VERSION ""

NS_ :

BS_:

BU_: CART BMS TB LV INV

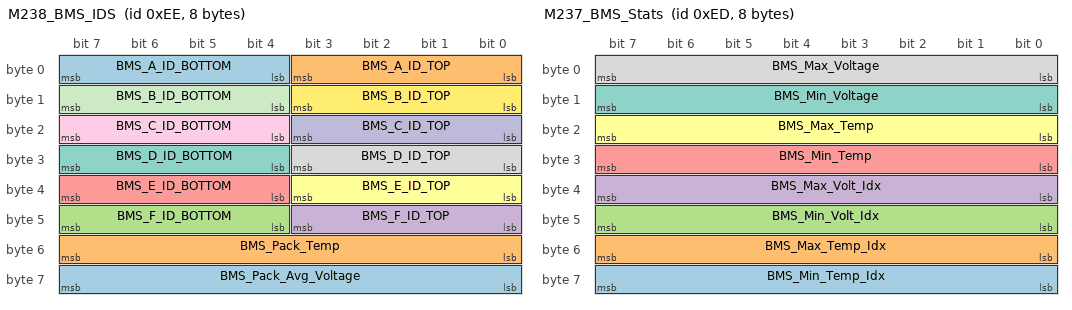
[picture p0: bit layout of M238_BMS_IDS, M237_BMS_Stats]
BO_ 238 M238_BMS_IDS: 8 Vector__XXX
 SG_ BMS_Pack_Avg_Voltage : 56|8@1+ (0.01,1.8) [1.8|4.35] "" Vector__XXX
 SG_ BMS_Pack_Temp : 48|8@1+ (0.25,0) [0|63.75] "" Vector__XXX
 SG_ BMS_F_ID_BOTTOM : 44|4@1+ (1,0) [0|15] "" Vector__XXX
 SG_ BMS_F_ID_TOP : 40|4@1+ (1,0) [0|15] "" Vector__XXX
 SG_ BMS_E_ID_BOTTOM : 36|4@1+ (1,0) [0|15] "" Vector__XXX
 SG_ BMS_E_ID_TOP : 32|4@1+ (1,0) [0|15] "" Vector__XXX
 SG_ BMS_D_ID_BOTTOM : 28|4@1+ (1,0) [0|15] "" Vector__XXX
 SG_ BMS_D_ID_TOP : 24|4@1+ (1,0) [0|15] "" Vector__XXX
 SG_ BMS_C_ID_BOTTOM : 20|4@1+ (1,0) [0|15] "" Vector__XXX
 SG_ BMS_C_ID_TOP : 16|4@1+ (1,0) [0|15] "" Vector__XXX
 SG_ BMS_B_ID_BOTTOM : 12|4@1+ (1,0) [0|15] "" Vector__XXX
 SG_ BMS_B_ID_TOP : 8|4@1+ (1,0) [0|15] "" Vector__XXX
 SG_ BMS_A_ID_BOTTOM : 4|4@1+ (1,0) [0|15] "" Vector__XXX
 SG_ BMS_A_ID_TOP : 0|4@1+ (1,0) [0|15] "" Vector__XXX

BO_ 237 M237_BMS_Stats: 8 Vector__XXX
 SG_ BMS_Min_Temp_Idx : 56|8@1+ (1,0) [0|0] "" Vector__XXX
 SG_ BMS_Max_Temp_Idx : 48|8@1+ (1,0) [0|0] "" Vector__XXX
 SG_ BMS_Min_Volt_Idx : 40|8@1+ (1,0) [0|0] "" Vector__XXX
 SG_ BMS_Max_Volt_Idx : 32|8@1+ (1,0) [0|0] "" Vector__XXX
 SG_ BMS_Min_Temp : 24|8@1+ (0.25,0) [0|63.75] "" Vector__XXX
 SG_ BMS_Max_Temp : 16|8@1+ (0.25,0) [0|63.75] "" Vector__XXX
 SG_ BMS_Min_Voltage : 8|8@1+ (0.01,1.8) [1.8|4.35] "" Vector__XXX
 SG_ BMS_Max_Voltage : 0|8@1+ (0.01,1.8) [1.8|4.35] "" Vector__XXX

BO_ 6 M006_Pack_Sense: 7 TB
 SG_ TB_Temp_Ambient : 48|8@1+ (0.5,-10) [-10|117.5] "C" Vector__XXX
 SG_ TB_Temp_VSense : 40|8@1+ (0.5,-10) [-10|117.5] "C" Vector__XXX
 SG_ TB_Temp_Power : 32|8@1+ (0.5,-10) [-10|117.5] "C" Vector__XXX
 SG_ TB_Temp_Precharge : 24|8@1+ (0.5,-10) [-10|117.5] "C" Vector__XXX
 SG_ TB_Bat_VSense : 12|12@1+ (0.25,0) [0|1023.75] "V" Vector__XXX
 SG_ TB_TS_VSense : 0|12@1+ (0.25,0) [0|1023.75] "V" Vector__XXX

BO_ 20 M020_Charger_to_Pack: 3 CART
 SG_ Charger_Balancing_Enable : 0|1@1+ (1,0) [0|1] "" Vector__XXX
 SG_ Charger_Current : 8|16@1- (0.1,0) [-3276.8|3276.7] "current:A" Vector__XXX

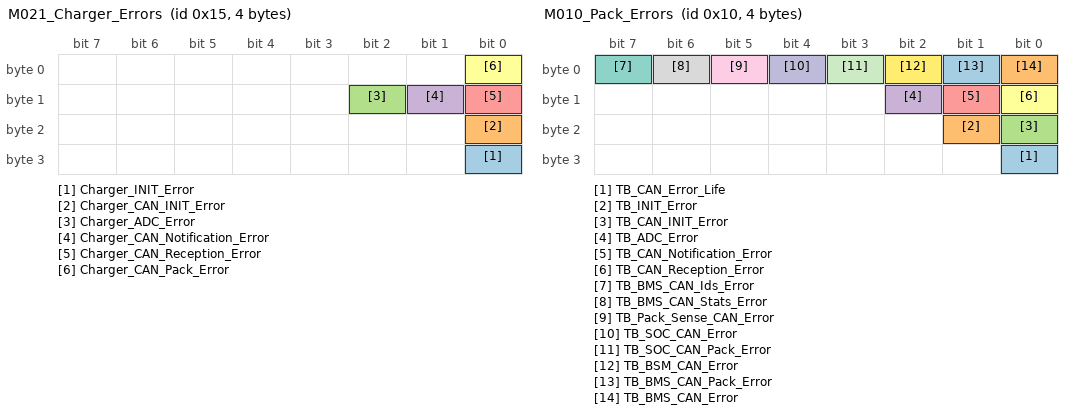
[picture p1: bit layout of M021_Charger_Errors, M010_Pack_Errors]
BO_ 21 M021_Charger_Errors: 4 CART
 SG_ Charger_INIT_Error : 24|1@1+ (1,0) [0|1] "" Vector__XXX
 SG_ Charger_CAN_INIT_Error : 16|1@1+ (1,0) [0|1] "" Vector__XXX
 SG_ Charger_ADC_Error : 10|1@1+ (1,0) [0|1] "" Vector__XXX
 SG_ Charger_CAN_Notification_Error : 9|1@1+ (1,0) [0|1] "" Vector__XXX
 SG_ Charger_CAN_Reception_Error : 8|1@1+ (1,0) [0|1] "" Vector__XXX
 SG_ Charger_CAN_Pack_Error : 0|1@1+ (1,0) [0|1] "" Vector__XXX

BO_ 16 M010_Pack_Errors: 4 TB
 SG_ TB_CAN_Error_Life : 24|1@1- (1,0) [0|0] "" Vector__XXX
 SG_ TB_INIT_Error : 17|1@1+ (1,0) [0|1] "" Vector__XXX
 SG_ TB_CAN_INIT_Error : 16|1@1+ (1,0) [0|1] "" Vector__XXX
 SG_ TB_ADC_Error : 10|1@1+ (1,0) [0|1] "" Vector__XXX
 SG_ TB_CAN_Notification_Error : 9|1@1+ (1,0) [0|1] "" Vector__XXX
 SG_ TB_CAN_Reception_Error : 8|1@1+ (1,0) [0|1] "" Vector__XXX
 SG_ TB_BMS_CAN_Ids_Error : 7|1@1+ (1,0) [0|1] "" Vector__XXX
 SG_ TB_BMS_CAN_Stats_Error : 6|1@1+ (1,0) [0|1] "" Vector__XXX
 SG_ TB_Pack_Sense_CAN_Error : 5|1@1+ (1,0) [0|1] "" Vector__XXX
 SG_ TB_SOC_CAN_Error : 4|1@1+ (1,0) [0|1] "" Vector__XXX
 SG_ TB_SOC_CAN_Pack_Error : 3|1@1+ (1,0) [0|1] "" Vector__XXX
 SG_ TB_BSM_CAN_Error : 2|1@1+ (1,0) [0|1] "" Vector__XXX
 SG_ TB_BMS_CAN_Pack_Error : 1|1@1+ (1,0) [0|1] "" Vector__XXX
 SG_ TB_BMS_CAN_Error : 0|1@1+ (1,0) [0|1] "" Vector__XXX

BO_ 236 M236_BMS_Pack: 8 BMS
 SG_ BMS_F_TEMP_SENSE_Fault : 60|1@1+ (1,0) [0|1] "" Vector__XXX
 SG_ BMS_F_COMMS_Fault : 59|1@1+ (1,0) [0|1] "" Vector__XXX
 SG_ BMS_F_OT_Fault : 58|1@1+ (1,0) [0|1] "" Vector__XXX
 SG_ BMS_F_UV_Fault : 57|1@1+ (1,0) [0|1] "" Vector__XXX
 SG_ BMS_F_OV_Fault : 56|1@1+ (1,0) [0|1] "" Vector__XXX
 SG_ BMS_E_TEMP_SENSE_Fault : 52|1@1+ (1,0) [0|1] "" Vector__XXX
 SG_ BMS_E_COMMS_Fault : 51|1@1+ (1,0) [0|1] "" Vector__XXX
 SG_ BMS_E_OT_Fault : 50|1@1+ (1,0) [0|1] "" Vector__XXX
 SG_ BMS_E_UV_Fault : 49|1@1+ (1,0) [0|1] "" Vector__XXX
 SG_ BMS_E_OV_Fault : 48|1@1+ (1,0) [0|1] "" Vector__XXX
 SG_ BMS_D_TEMP_SENSE_Fault : 44|1@1+ (1,0) [0|1] "" Vector__XXX
 SG_ BMS_D_COMMS_Fault : 43|1@1+ (1,0) [0|1] "" Vector__XXX
 SG_ BMS_D_OT_Fault : 42|1@1+ (1,0) [0|1] "" Vector__XXX
 SG_ BMS_D_UV_Fault : 41|1@1+ (1,0) [0|1] "" Vector__XXX
 SG_ BMS_D_OV_Fault : 40|1@1+ (1,0) [0|1] "" Vector__XXX
 SG_ BMS_C_TEMP_SENSE_Fault : 36|1@1+ (1,0) [0|1] "" Vector__XXX
 SG_ BMS_C_COMMS_Fault : 35|1@1+ (1,0) [0|1] "" Vector__XXX
 SG_ BMS_C_OT_Fault : 34|1@1+ (1,0) [0|1] "" Vector__XXX
 SG_ BMS_C_UV_Fault : 33|1@1+ (1,0) [0|1] "" Vector__XXX
 SG_ BMS_C_OV_Fault : 32|1@1+ (1,0) [0|1] "" Vector__XXX
 SG_ BMS_B_TEMP_SENSE_Fault : 28|1@1+ (1,0) [0|1] "" Vector__XXX
 SG_ BMS_B_COMMS_Fault : 27|1@1+ (1,0) [0|1] "" Vector__XXX
 SG_ BMS_B_OT_Fault : 26|1@1+ (1,0) [0|1] "" Vector__XXX
 SG_ BMS_B_UV_Fault : 25|1@1+ (1,0) [0|1] "" Vector__XXX
 SG_ BMS_B_OV_Fault : 24|1@1+ (1,0) [0|1] "" Vector__XXX
 SG_ BMS_Balancing_Done : 23|1@1+ (1,0) [0|1] "" Vector__XXX
 SG_ BMS_A_TEMP_SENSE_Fault : 20|1@1+ (1,0) [0|1] "" Vector__XXX
 SG_ BMS_A_COMMS_Fault : 19|1@1+ (1,0) [0|1] "" Vector__XXX
 SG_ BMS_A_OT_Fault : 18|1@1+ (1,0) [0|1] "" Vector__XXX
 SG_ BMS_A_UV_Fault : 17|1@1+ (1,0) [0|1] "" Vector__XXX
 SG_ BMS_A_OV_Fault : 16|1@1+ (1,0) [0|1] "" Vector__XXX
 SG_ BMS_Pack_Voltage : 0|16@1+ (0.01,0) [0|655.35] "" Vector__XXX

BO_ 240 M240_BMS_SOC_Pack: 6 BMS
 SG_ BMS_SOC_Uncertainty : 32|16@1+ (1.52590218966964E-05,0) [0|1] "" Vector__XXX
 SG_ BMS_SOC_Pack_Capacity : 16|16@1+ (0.02285191119,0) [0|1497.59999983665] "" Vector__XXX
 SG_ BMS_SOC_Pack : 0|16@1+ (1.52590218966964E-05,0) [0|1] "" Vector__XXX

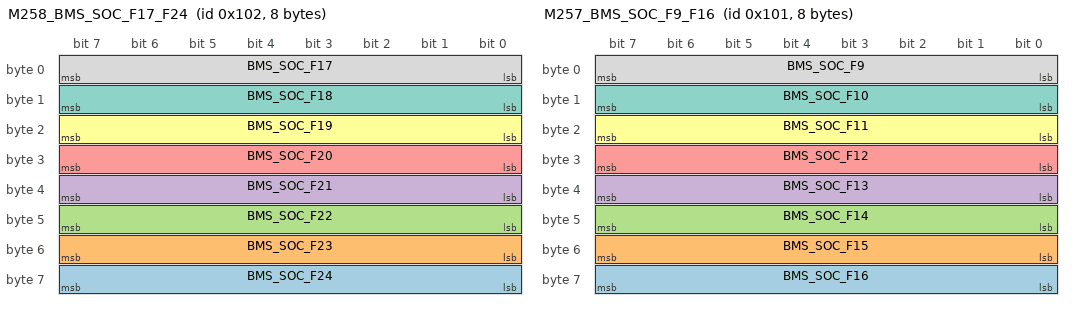
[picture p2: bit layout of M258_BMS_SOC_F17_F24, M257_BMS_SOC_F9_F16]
BO_ 258 M258_BMS_SOC_F17_F24: 8 BMS
 SG_ BMS_SOC_F24 : 56|8@1+ (0.00392156862745098,0) [0|1] "" Vector__XXX
 SG_ BMS_SOC_F23 : 48|8@1+ (0.00392156862745098,0) [0|1] "" Vector__XXX
 SG_ BMS_SOC_F22 : 40|8@1+ (0.00392156862745098,0) [0|1] "" Vector__XXX
 SG_ BMS_SOC_F21 : 32|8@1+ (0.00392156862745098,0) [0|1] "" Vector__XXX
 SG_ BMS_SOC_F20 : 24|8@1+ (0.00392156862745098,0) [0|1] "" Vector__XXX
 SG_ BMS_SOC_F19 : 16|8@1+ (0.00392156862745098,0) [0|1] "" Vector__XXX
 SG_ BMS_SOC_F18 : 8|8@1+ (0.00392156862745098,0) [0|1] "" Vector__XXX
 SG_ BMS_SOC_F17 : 0|8@1+ (0.00392156862745098,0) [0|1] "" Vector__XXX

BO_ 257 M257_BMS_SOC_F9_F16: 8 BMS
 SG_ BMS_SOC_F16 : 56|8@1+ (0.00392156862745098,0) [0|1] "" Vector__XXX
 SG_ BMS_SOC_F15 : 48|8@1+ (0.00392156862745098,0) [0|1] "" Vector__XXX
 SG_ BMS_SOC_F14 : 40|8@1+ (0.00392156862745098,0) [0|1] "" Vector__XXX
 SG_ BMS_SOC_F13 : 32|8@1+ (0.00392156862745098,0) [0|1] "" Vector__XXX
 SG_ BMS_SOC_F12 : 24|8@1+ (0.00392156862745098,0) [0|1] "" Vector__XXX
 SG_ BMS_SOC_F11 : 16|8@1+ (0.00392156862745098,0) [0|1] "" Vector__XXX
 SG_ BMS_SOC_F10 : 8|8@1+ (0.00392156862745098,0) [0|1] "" Vector__XXX
 SG_ BMS_SOC_F9 : 0|8@1+ (0.00392156862745098,0) [0|1] "" Vector__XXX

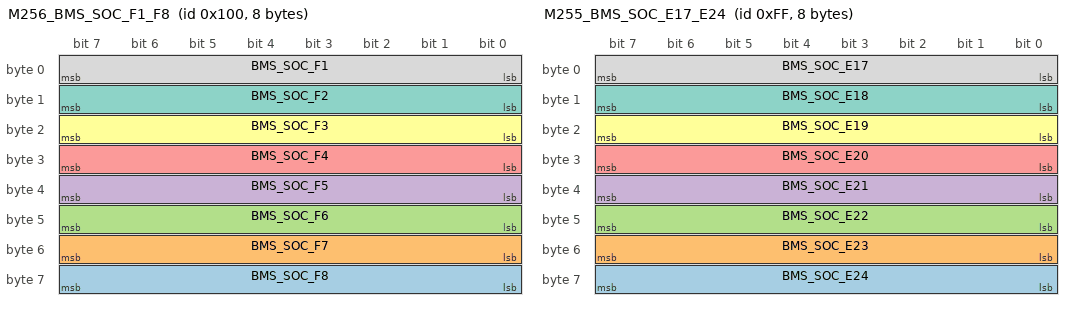
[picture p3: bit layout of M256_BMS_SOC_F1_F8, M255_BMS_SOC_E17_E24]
BO_ 256 M256_BMS_SOC_F1_F8: 8 BMS
 SG_ BMS_SOC_F8 : 56|8@1+ (0.00392156862745098,0) [0|1] "" Vector__XXX
 SG_ BMS_SOC_F7 : 48|8@1+ (0.00392156862745098,0) [0|1] "" Vector__XXX
 SG_ BMS_SOC_F6 : 40|8@1+ (0.00392156862745098,0) [0|1] "" Vector__XXX
 SG_ BMS_SOC_F5 : 32|8@1+ (0.00392156862745098,0) [0|1] "" Vector__XXX
 SG_ BMS_SOC_F4 : 24|8@1+ (0.00392156862745098,0) [0|1] "" Vector__XXX
 SG_ BMS_SOC_F3 : 16|8@1+ (0.00392156862745098,0) [0|1] "" Vector__XXX
 SG_ BMS_SOC_F2 : 8|8@1+ (0.00392156862745098,0) [0|1] "" Vector__XXX
 SG_ BMS_SOC_F1 : 0|8@1+ (0.00392156862745098,0) [0|1] "" Vector__XXX

BO_ 255 M255_BMS_SOC_E17_E24: 8 BMS
 SG_ BMS_SOC_E24 : 56|8@1+ (0.00392156862745098,0) [0|1] "" Vector__XXX
 SG_ BMS_SOC_E23 : 48|8@1+ (0.00392156862745098,0) [0|1] "" Vector__XXX
 SG_ BMS_SOC_E22 : 40|8@1+ (0.00392156862745098,0) [0|1] "" Vector__XXX
 SG_ BMS_SOC_E21 : 32|8@1+ (0.00392156862745098,0) [0|1] "" Vector__XXX
 SG_ BMS_SOC_E20 : 24|8@1+ (0.00392156862745098,0) [0|1] "" Vector__XXX
 SG_ BMS_SOC_E19 : 16|8@1+ (0.00392156862745098,0) [0|1] "" Vector__XXX
 SG_ BMS_SOC_E18 : 8|8@1+ (0.00392156862745098,0) [0|1] "" Vector__XXX
 SG_ BMS_SOC_E17 : 0|8@1+ (0.00392156862745098,0) [0|1] "" Vector__XXX

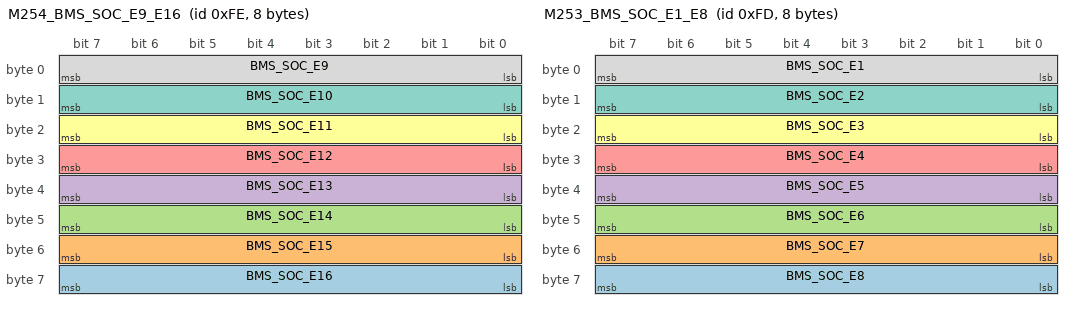
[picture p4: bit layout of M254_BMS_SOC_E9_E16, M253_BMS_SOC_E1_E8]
BO_ 254 M254_BMS_SOC_E9_E16: 8 BMS
 SG_ BMS_SOC_E16 : 56|8@1+ (0.00392156862745098,0) [0|1] "" Vector__XXX
 SG_ BMS_SOC_E15 : 48|8@1+ (0.00392156862745098,0) [0|1] "" Vector__XXX
 SG_ BMS_SOC_E14 : 40|8@1+ (0.00392156862745098,0) [0|1] "" Vector__XXX
 SG_ BMS_SOC_E13 : 32|8@1+ (0.00392156862745098,0) [0|1] "" Vector__XXX
 SG_ BMS_SOC_E12 : 24|8@1+ (0.00392156862745098,0) [0|1] "" Vector__XXX
 SG_ BMS_SOC_E11 : 16|8@1+ (0.00392156862745098,0) [0|1] "" Vector__XXX
 SG_ BMS_SOC_E10 : 8|8@1+ (0.00392156862745098,0) [0|1] "" Vector__XXX
 SG_ BMS_SOC_E9 : 0|8@1+ (0.00392156862745098,0) [0|1] "" Vector__XXX

BO_ 253 M253_BMS_SOC_E1_E8: 8 BMS
 SG_ BMS_SOC_E8 : 56|8@1+ (0.00392156862745098,0) [0|1] "" Vector__XXX
 SG_ BMS_SOC_E7 : 48|8@1+ (0.00392156862745098,0) [0|1] "" Vector__XXX
 SG_ BMS_SOC_E6 : 40|8@1+ (0.00392156862745098,0) [0|1] "" Vector__XXX
 SG_ BMS_SOC_E5 : 32|8@1+ (0.00392156862745098,0) [0|1] "" Vector__XXX
 SG_ BMS_SOC_E4 : 24|8@1+ (0.00392156862745098,0) [0|1] "" Vector__XXX
 SG_ BMS_SOC_E3 : 16|8@1+ (0.00392156862745098,0) [0|1] "" Vector__XXX
 SG_ BMS_SOC_E2 : 8|8@1+ (0.00392156862745098,0) [0|1] "" Vector__XXX
 SG_ BMS_SOC_E1 : 0|8@1+ (0.00392156862745098,0) [0|1] "" Vector__XXX

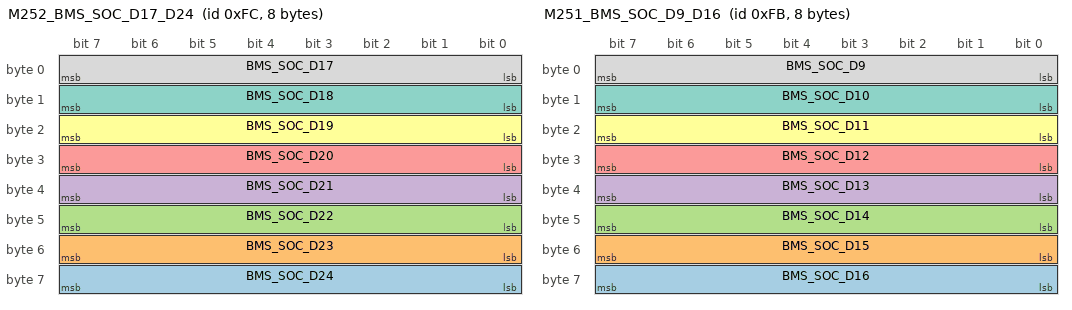
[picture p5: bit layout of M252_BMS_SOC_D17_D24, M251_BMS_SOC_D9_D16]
BO_ 252 M252_BMS_SOC_D17_D24: 8 BMS
 SG_ BMS_SOC_D24 : 56|8@1+ (0.00392156862745098,0) [0|1] "" Vector__XXX
 SG_ BMS_SOC_D23 : 48|8@1+ (0.00392156862745098,0) [0|1] "" Vector__XXX
 SG_ BMS_SOC_D22 : 40|8@1+ (0.00392156862745098,0) [0|1] "" Vector__XXX
 SG_ BMS_SOC_D21 : 32|8@1+ (0.00392156862745098,0) [0|1] "" Vector__XXX
 SG_ BMS_SOC_D20 : 24|8@1+ (0.00392156862745098,0) [0|1] "" Vector__XXX
 SG_ BMS_SOC_D19 : 16|8@1+ (0.00392156862745098,0) [0|1] "" Vector__XXX
 SG_ BMS_SOC_D18 : 8|8@1+ (0.00392156862745098,0) [0|1] "" Vector__XXX
 SG_ BMS_SOC_D17 : 0|8@1+ (0.00392156862745098,0) [0|1] "" Vector__XXX

BO_ 251 M251_BMS_SOC_D9_D16: 8 BMS
 SG_ BMS_SOC_D16 : 56|8@1+ (0.00392156862745098,0) [0|1] "" Vector__XXX
 SG_ BMS_SOC_D15 : 48|8@1+ (0.00392156862745098,0) [0|1] "" Vector__XXX
 SG_ BMS_SOC_D14 : 40|8@1+ (0.00392156862745098,0) [0|1] "" Vector__XXX
 SG_ BMS_SOC_D13 : 32|8@1+ (0.00392156862745098,0) [0|1] "" Vector__XXX
 SG_ BMS_SOC_D12 : 24|8@1+ (0.00392156862745098,0) [0|1] "" Vector__XXX
 SG_ BMS_SOC_D11 : 16|8@1+ (0.00392156862745098,0) [0|1] "" Vector__XXX
 SG_ BMS_SOC_D10 : 8|8@1+ (0.00392156862745098,0) [0|1] "" Vector__XXX
 SG_ BMS_SOC_D9 : 0|8@1+ (0.00392156862745098,0) [0|1] "" Vector__XXX

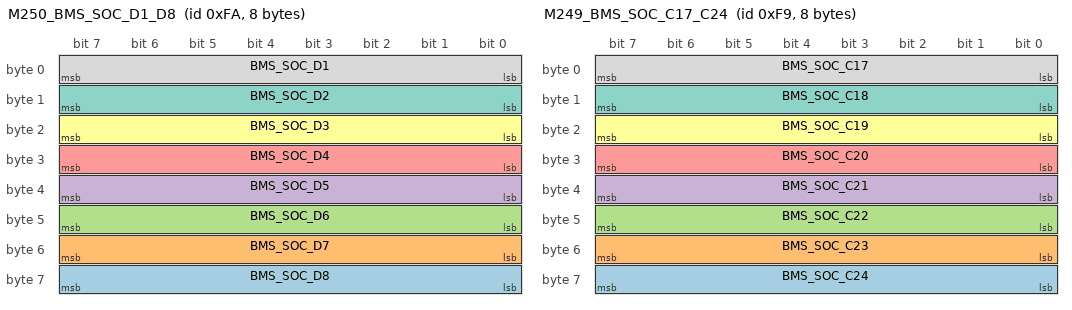
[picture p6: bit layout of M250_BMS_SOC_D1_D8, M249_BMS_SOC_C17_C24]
BO_ 250 M250_BMS_SOC_D1_D8: 8 BMS
 SG_ BMS_SOC_D8 : 56|8@1+ (0.00392156862745098,0) [0|1] "" Vector__XXX
 SG_ BMS_SOC_D7 : 48|8@1+ (0.00392156862745098,0) [0|1] "" Vector__XXX
 SG_ BMS_SOC_D6 : 40|8@1+ (0.00392156862745098,0) [0|1] "" Vector__XXX
 SG_ BMS_SOC_D5 : 32|8@1+ (0.00392156862745098,0) [0|1] "" Vector__XXX
 SG_ BMS_SOC_D4 : 24|8@1+ (0.00392156862745098,0) [0|1] "" Vector__XXX
 SG_ BMS_SOC_D3 : 16|8@1+ (0.00392156862745098,0) [0|1] "" Vector__XXX
 SG_ BMS_SOC_D2 : 8|8@1+ (0.00392156862745098,0) [0|1] "" Vector__XXX
 SG_ BMS_SOC_D1 : 0|8@1+ (0.00392156862745098,0) [0|1] "" Vector__XXX

BO_ 249 M249_BMS_SOC_C17_C24: 8 BMS
 SG_ BMS_SOC_C24 : 56|8@1+ (0.00392156862745098,0) [0|1] "" Vector__XXX
 SG_ BMS_SOC_C23 : 48|8@1+ (0.00392156862745098,0) [0|1] "" Vector__XXX
 SG_ BMS_SOC_C22 : 40|8@1+ (0.00392156862745098,0) [0|1] "" Vector__XXX
 SG_ BMS_SOC_C21 : 32|8@1+ (0.00392156862745098,0) [0|1] "" Vector__XXX
 SG_ BMS_SOC_C20 : 24|8@1+ (0.00392156862745098,0) [0|1] "" Vector__XXX
 SG_ BMS_SOC_C19 : 16|8@1+ (0.00392156862745098,0) [0|1] "" Vector__XXX
 SG_ BMS_SOC_C18 : 8|8@1+ (0.00392156862745098,0) [0|1] "" Vector__XXX
 SG_ BMS_SOC_C17 : 0|8@1+ (0.00392156862745098,0) [0|1] "" Vector__XXX

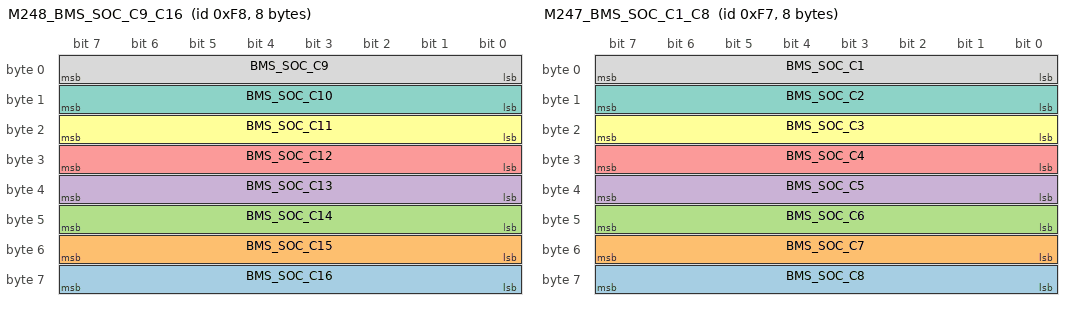
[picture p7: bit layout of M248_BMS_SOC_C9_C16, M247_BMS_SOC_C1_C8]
BO_ 248 M248_BMS_SOC_C9_C16: 8 BMS
 SG_ BMS_SOC_C16 : 56|8@1+ (0.00392156862745098,0) [0|1] "" Vector__XXX
 SG_ BMS_SOC_C15 : 48|8@1+ (0.00392156862745098,0) [0|1] "" Vector__XXX
 SG_ BMS_SOC_C14 : 40|8@1+ (0.00392156862745098,0) [0|1] "" Vector__XXX
 SG_ BMS_SOC_C13 : 32|8@1+ (0.00392156862745098,0) [0|1] "" Vector__XXX
 SG_ BMS_SOC_C12 : 24|8@1+ (0.00392156862745098,0) [0|1] "" Vector__XXX
 SG_ BMS_SOC_C11 : 16|8@1+ (0.00392156862745098,0) [0|1] "" Vector__XXX
 SG_ BMS_SOC_C10 : 8|8@1+ (0.00392156862745098,0) [0|1] "" Vector__XXX
 SG_ BMS_SOC_C9 : 0|8@1+ (0.00392156862745098,0) [0|1] "" Vector__XXX

BO_ 247 M247_BMS_SOC_C1_C8: 8 BMS
 SG_ BMS_SOC_C8 : 56|8@1+ (0.00392156862745098,0) [0|1] "" Vector__XXX
 SG_ BMS_SOC_C7 : 48|8@1+ (0.00392156862745098,0) [0|1] "" Vector__XXX
 SG_ BMS_SOC_C6 : 40|8@1+ (0.00392156862745098,0) [0|1] "" Vector__XXX
 SG_ BMS_SOC_C5 : 32|8@1+ (0.00392156862745098,0) [0|1] "" Vector__XXX
 SG_ BMS_SOC_C4 : 24|8@1+ (0.00392156862745098,0) [0|1] "" Vector__XXX
 SG_ BMS_SOC_C3 : 16|8@1+ (0.00392156862745098,0) [0|1] "" Vector__XXX
 SG_ BMS_SOC_C2 : 8|8@1+ (0.00392156862745098,0) [0|1] "" Vector__XXX
 SG_ BMS_SOC_C1 : 0|8@1+ (0.00392156862745098,0) [0|1] "" Vector__XXX

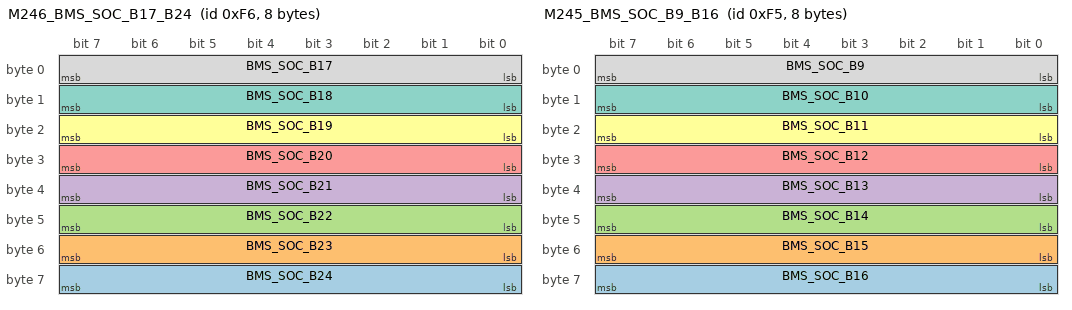
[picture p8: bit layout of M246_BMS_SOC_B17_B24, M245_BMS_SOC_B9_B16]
BO_ 246 M246_BMS_SOC_B17_B24: 8 BMS
 SG_ BMS_SOC_B24 : 56|8@1+ (0.00392156862745098,0) [0|1] "" Vector__XXX
 SG_ BMS_SOC_B23 : 48|8@1+ (0.00392156862745098,0) [0|1] "" Vector__XXX
 SG_ BMS_SOC_B22 : 40|8@1+ (0.00392156862745098,0) [0|1] "" Vector__XXX
 SG_ BMS_SOC_B21 : 32|8@1+ (0.00392156862745098,0) [0|1] "" Vector__XXX
 SG_ BMS_SOC_B20 : 24|8@1+ (0.00392156862745098,0) [0|1] "" Vector__XXX
 SG_ BMS_SOC_B19 : 16|8@1+ (0.00392156862745098,0) [0|1] "" Vector__XXX
 SG_ BMS_SOC_B18 : 8|8@1+ (0.00392156862745098,0) [0|1] "" Vector__XXX
 SG_ BMS_SOC_B17 : 0|8@1+ (0.00392156862745098,0) [0|1] "" Vector__XXX

BO_ 245 M245_BMS_SOC_B9_B16: 8 BMS
 SG_ BMS_SOC_B16 : 56|8@1+ (0.00392156862745098,0) [0|1] "" Vector__XXX
 SG_ BMS_SOC_B15 : 48|8@1+ (0.00392156862745098,0) [0|1] "" Vector__XXX
 SG_ BMS_SOC_B14 : 40|8@1+ (0.00392156862745098,0) [0|1] "" Vector__XXX
 SG_ BMS_SOC_B13 : 32|8@1+ (0.00392156862745098,0) [0|1] "" Vector__XXX
 SG_ BMS_SOC_B12 : 24|8@1+ (0.00392156862745098,0) [0|1] "" Vector__XXX
 SG_ BMS_SOC_B11 : 16|8@1+ (0.00392156862745098,0) [0|1] "" Vector__XXX
 SG_ BMS_SOC_B10 : 8|8@1+ (0.00392156862745098,0) [0|1] "" Vector__XXX
 SG_ BMS_SOC_B9 : 0|8@1+ (0.00392156862745098,0) [0|1] "" Vector__XXX

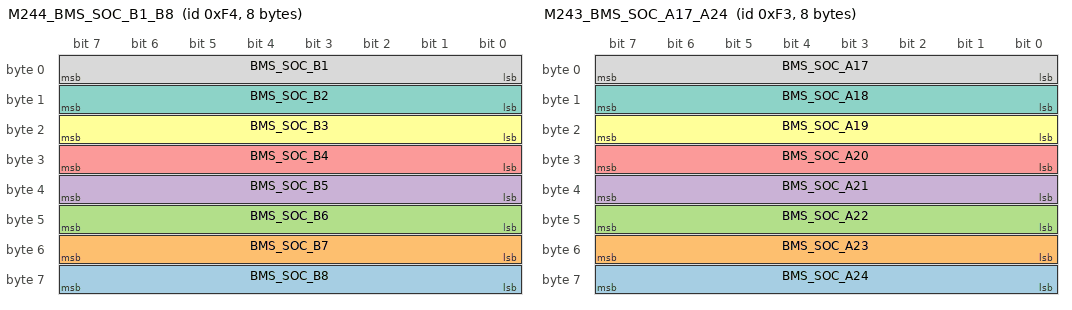
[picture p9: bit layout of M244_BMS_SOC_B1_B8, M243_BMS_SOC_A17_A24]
BO_ 244 M244_BMS_SOC_B1_B8: 8 BMS
 SG_ BMS_SOC_B8 : 56|8@1+ (0.00392156862745098,0) [0|1] "" Vector__XXX
 SG_ BMS_SOC_B7 : 48|8@1+ (0.00392156862745098,0) [0|1] "" Vector__XXX
 SG_ BMS_SOC_B6 : 40|8@1+ (0.00392156862745098,0) [0|1] "" Vector__XXX
 SG_ BMS_SOC_B5 : 32|8@1+ (0.00392156862745098,0) [0|1] "" Vector__XXX
 SG_ BMS_SOC_B4 : 24|8@1+ (0.00392156862745098,0) [0|1] "" Vector__XXX
 SG_ BMS_SOC_B3 : 16|8@1+ (0.00392156862745098,0) [0|1] "" Vector__XXX
 SG_ BMS_SOC_B2 : 8|8@1+ (0.00392156862745098,0) [0|1] "" Vector__XXX
 SG_ BMS_SOC_B1 : 0|8@1+ (0.00392156862745098,0) [0|1] "" Vector__XXX

BO_ 243 M243_BMS_SOC_A17_A24: 8 BMS
 SG_ BMS_SOC_A24 : 56|8@1+ (0.00392156862745098,0) [0|1] "" Vector__XXX
 SG_ BMS_SOC_A23 : 48|8@1+ (0.00392156862745098,0) [0|1] "" Vector__XXX
 SG_ BMS_SOC_A22 : 40|8@1+ (0.00392156862745098,0) [0|1] "" Vector__XXX
 SG_ BMS_SOC_A21 : 32|8@1+ (0.00392156862745098,0) [0|1] "" Vector__XXX
 SG_ BMS_SOC_A20 : 24|8@1+ (0.00392156862745098,0) [0|1] "" Vector__XXX
 SG_ BMS_SOC_A19 : 16|8@1+ (0.00392156862745098,0) [0|1] "" Vector__XXX
 SG_ BMS_SOC_A18 : 8|8@1+ (0.00392156862745098,0) [0|1] "" Vector__XXX
 SG_ BMS_SOC_A17 : 0|8@1+ (0.00392156862745098,0) [0|1] "" Vector__XXX

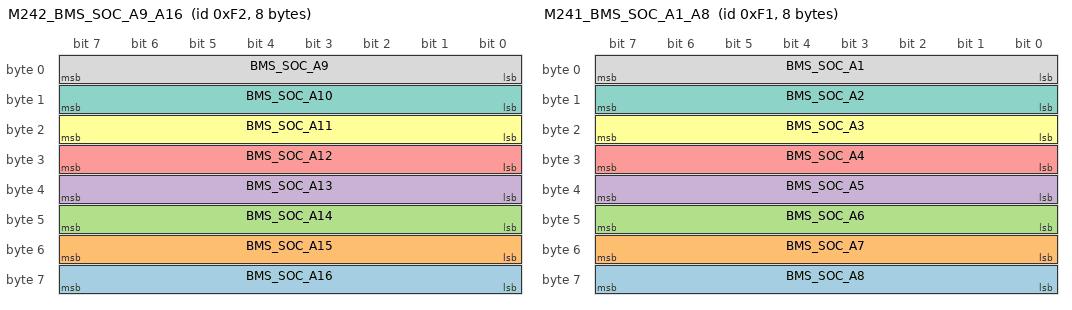
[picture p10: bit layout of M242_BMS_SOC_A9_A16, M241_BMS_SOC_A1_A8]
BO_ 242 M242_BMS_SOC_A9_A16: 8 BMS
 SG_ BMS_SOC_A16 : 56|8@1+ (0.00392156862745098,0) [0|1] "" Vector__XXX
 SG_ BMS_SOC_A15 : 48|8@1+ (0.00392156862745098,0) [0|1] "" Vector__XXX
 SG_ BMS_SOC_A14 : 40|8@1+ (0.00392156862745098,0) [0|1] "" Vector__XXX
 SG_ BMS_SOC_A13 : 32|8@1+ (0.00392156862745098,0) [0|1] "" Vector__XXX
 SG_ BMS_SOC_A12 : 24|8@1+ (0.00392156862745098,0) [0|1] "" Vector__XXX
 SG_ BMS_SOC_A11 : 16|8@1+ (0.00392156862745098,0) [0|1] "" Vector__XXX
 SG_ BMS_SOC_A10 : 8|8@1+ (0.00392156862745098,0) [0|1] "" Vector__XXX
 SG_ BMS_SOC_A9 : 0|8@1+ (0.00392156862745098,0) [0|1] "" Vector__XXX

BO_ 241 M241_BMS_SOC_A1_A8: 8 BMS
 SG_ BMS_SOC_A8 : 56|8@1+ (0.00392156862745098,0) [0|1] "" Vector__XXX
 SG_ BMS_SOC_A7 : 48|8@1+ (0.00392156862745098,0) [0|1] "" Vector__XXX
 SG_ BMS_SOC_A6 : 40|8@1+ (0.00392156862745098,0) [0|1] "" Vector__XXX
 SG_ BMS_SOC_A5 : 32|8@1+ (0.00392156862745098,0) [0|1] "" Vector__XXX
 SG_ BMS_SOC_A4 : 24|8@1+ (0.00392156862745098,0) [0|1] "" Vector__XXX
 SG_ BMS_SOC_A3 : 16|8@1+ (0.00392156862745098,0) [0|1] "" Vector__XXX
 SG_ BMS_SOC_A2 : 8|8@1+ (0.00392156862745098,0) [0|1] "" Vector__XXX
 SG_ BMS_SOC_A1 : 0|8@1+ (0.00392156862745098,0) [0|1] "" Vector__XXX

BO_ 406 M406_Board_Signals: 8 LV
 SG_ LV_Driver_Torque_Switch : 56|1@1+ (1,0) [0|1] "" Vector__XXX
 SG_ LV_MCU_Torque_Ctrl : 12|3@1+ (1,0) [0|7] "" Vector__XXX
 SG_ LV_Dash_Pot_3 : 48|8@1+ (20,0) [0|5100] "" Vector__XXX
 SG_ LV_CT_Sig : 32|16@1- (1,0) [-32768|32767] "" Vector__XXX
 SG_ LV_BSE_Sig : 16|16@1- (1,0) [-32768|32767] "" Vector__XXX
 SG_ LV_Reset_Sig : 10|1@1+ (1,0) [0|1] "" Vector__XXX
 SG_ LV_SDC_Sig : 11|1@1+ (1,0) [0|1] "" Vector__XXX
 SG_ LV_SDC_Sig_Final : 9|1@1+ (1,0) [0|1] "" Vector__XXX
 SG_ LV_Start_Up_Active : 8|1@1+ (1,0) [0|1] "" Vector__XXX
 SG_ LV_BSPD_Fault : 7|1@1+ (1,0) [0|1] "" Vector__XXX
 SG_ LV_BSPD_Dual_Check : 6|1@1+ (1,0) [0|1] "" Vector__XXX
 SG_ LV_CT_OC : 5|1@1+ (1,0) [0|1] "" Vector__XXX
 SG_ LV_CT_SC : 4|1@1+ (1,0) [0|1] "" Vector__XXX
 SG_ LV_BPT_OC : 3|1@1+ (1,0) [0|1] "" Vector__XXX
 SG_ LV_BPT_SC : 2|1@1+ (1,0) [0|1] "" Vector__XXX
 SG_ LV_BMS_Good : 1|1@1+ (1,0) [0|1] "" Vector__XXX
 SG_ LV_IMD_Good : 0|1@1+ (1,0) [0|1] "" Vector__XXX

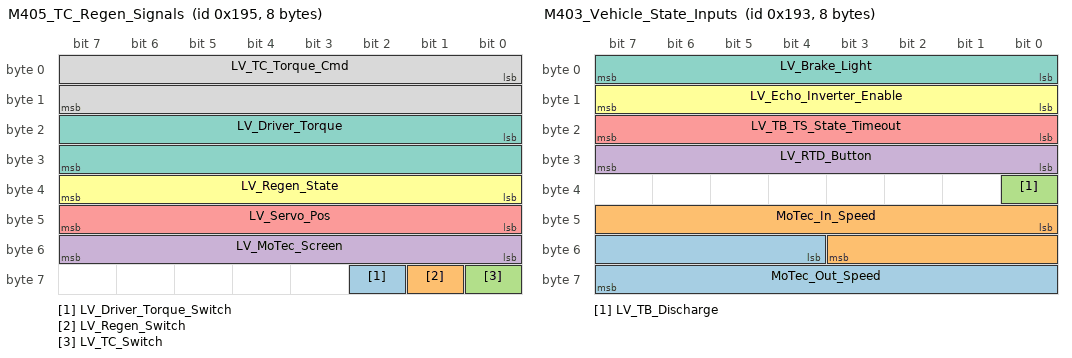
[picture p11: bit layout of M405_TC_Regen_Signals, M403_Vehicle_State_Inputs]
BO_ 405 M405_TC_Regen_Signals: 8 LV
 SG_ LV_Driver_Torque_Switch : 58|1@1+ (1,0) [0|1] "" Vector__XXX
 SG_ LV_Regen_Switch : 57|1@1+ (1,0) [0|1] "" Vector__XXX
 SG_ LV_TC_Switch : 56|1@1+ (1,0) [0|1] "" Vector__XXX
 SG_ LV_MoTec_Screen : 48|8@1+ (1,0) [0|255] "" Vector__XXX
 SG_ LV_Servo_Pos : 40|8@1- (160.62745098,0) [-20560.31372544|20399.68627446] "" Vector__XXX
 SG_ LV_Regen_State : 32|8@1- (1,0) [-128|127] "" Vector__XXX
 SG_ LV_Driver_Torque : 16|16@1- (0.1,0) [-3276.8|3276.7] "torque:N.m" Vector__XXX
 SG_ LV_TC_Torque_Cmd : 0|16@1- (0.1,0) [-3276.8|3276.7] "" Vector__XXX

BO_ 404 M404_LV_V_Kalman_Outputs: 8 LV
 SG_ LV_SR : 48|16@1- (0.0001,0) [-3.2768|3.2767] "" Vector__XXX
 SG_ LV_COV_V : 32|16@1+ (0.02,0) [0|1310.7] "" Vector__XXX
 SG_ LV_FILTERED_A : 16|16@1- (0.01,0) [-327.68|327.67] "" Vector__XXX
 SG_ LV_FILTERED_V : 0|16@1+ (0.1,0) [0|6553.5] "" Vector__XXX

BO_ 52 M052_G_Forces: 8 Vector__XXX
 SG_ LV_IMU_Angular_Rate : 56|8@1- (1,0) [-128|127] "" Vector__XXX
 SG_ LV_IMU_Acceleration : 48|8@1- (0.1,0) [-12.8|12.7] "" Vector__XXX
 SG_ SEN_G_FORCE_Z : 32|16@1- (0.01,0) [-327.68|327.67] "" Vector__XXX
 SG_ SEN_G_FORCE_Y : 16|16@1- (0.01,0) [-327.68|327.67] "" Vector__XXX
 SG_ SEN_G_FORCE_X : 0|16@1- (0.01,0) [-327.68|327.67] "" Vector__XXX

BO_ 51 M051_Wheel_Speeds: 8 Vector__XXX
 SG_ SEN_WSS_RR : 48|16@1+ (0.1,0) [0|6553.5] "" Vector__XXX
 SG_ SEN_WSS_RL : 32|16@1+ (0.1,0) [0|6553.5] "" Vector__XXX
 SG_ SEN_WSS_FR : 16|16@1+ (0.1,0) [0|163.8375] "" Vector__XXX
 SG_ SEN_WSS_FL : 0|16@1+ (0.1,0) [0|6553.5] "" Vector__XXX

BO_ 403 M403_Vehicle_State_Inputs: 8 LV
 SG_ MoTec_Out_Speed : 52|12@1+ (0.1,0) [0|409.5] "" Vector__XXX
 SG_ MoTec_In_Speed : 40|12@1+ (0.1,0) [0|409.5] "" Vector__XXX
 SG_ LV_TB_Discharge : 32|1@1+ (1,0) [0|1] "" Vector__XXX
 SG_ LV_RTD_Button : 24|8@1+ (1,0) [0|0] "" Vector__XXX
 SG_ LV_TB_TS_State_Timeout : 16|8@1- (1,0) [0|0] "" Vector__XXX
 SG_ LV_Echo_Inverter_Enable : 8|8@1- (1,0) [0|0] "" Vector__XXX
 SG_ LV_Brake_Light : 0|8@1+ (1,0) [0|0] "" Vector__XXX

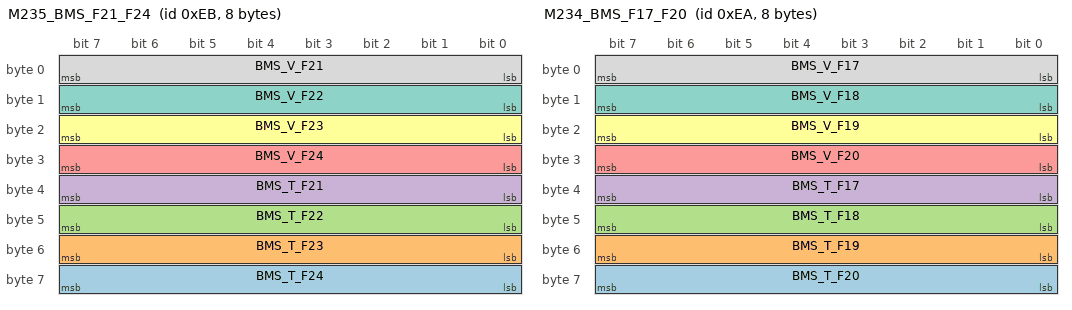
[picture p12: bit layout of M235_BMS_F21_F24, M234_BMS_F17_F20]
BO_ 235 M235_BMS_F21_F24: 8 BMS
 SG_ BMS_T_F24 : 56|8@1+ (0.25,0) [0|63.75] "temperature:C" Vector__XXX
 SG_ BMS_T_F23 : 48|8@1+ (0.25,0) [0|63.75] "temperature:C" Vector__XXX
 SG_ BMS_T_F22 : 40|8@1+ (0.25,0) [0|63.75] "temperature:C" Vector__XXX
 SG_ BMS_T_F21 : 32|8@1+ (0.25,0) [0|63.75] "temperature:C" Vector__XXX
 SG_ BMS_V_F24 : 24|8@1+ (0.01,1.8) [1.8|4.35] "voltage:V" Vector__XXX
 SG_ BMS_V_F23 : 16|8@1+ (0.01,1.8) [1.8|4.35] "voltage:V" Vector__XXX
 SG_ BMS_V_F22 : 8|8@1+ (0.01,1.8) [1.8|4.35] "voltage:V" Vector__XXX
 SG_ BMS_V_F21 : 0|8@1+ (0.01,1.8) [1.8|4.35] "voltage:V" Vector__XXX

BO_ 234 M234_BMS_F17_F20: 8 BMS
 SG_ BMS_T_F20 : 56|8@1+ (0.25,0) [0|63.75] "temperature:C" Vector__XXX
 SG_ BMS_T_F19 : 48|8@1+ (0.25,0) [0|63.75] "temperature:C" Vector__XXX
 SG_ BMS_T_F18 : 40|8@1+ (0.25,0) [0|63.75] "temperature:C" Vector__XXX
 SG_ BMS_T_F17 : 32|8@1+ (0.25,0) [0|63.75] "temperature:C" Vector__XXX
 SG_ BMS_V_F20 : 24|8@1+ (0.01,1.8) [1.8|4.35] "voltage:V" Vector__XXX
 SG_ BMS_V_F19 : 16|8@1+ (0.01,1.8) [1.8|4.35] "voltage:V" Vector__XXX
 SG_ BMS_V_F18 : 8|8@1+ (0.01,1.8) [1.8|4.35] "voltage:V" Vector__XXX
 SG_ BMS_V_F17 : 0|8@1+ (0.01,1.8) [1.8|4.35] "voltage:V" Vector__XXX

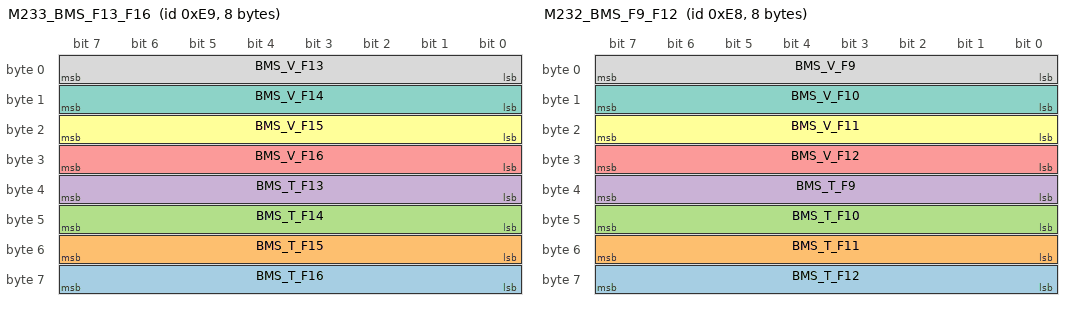
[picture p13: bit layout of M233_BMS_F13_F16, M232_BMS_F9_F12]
BO_ 233 M233_BMS_F13_F16: 8 BMS
 SG_ BMS_T_F16 : 56|8@1+ (0.25,0) [0|63.75] "temperature:C" Vector__XXX
 SG_ BMS_T_F15 : 48|8@1+ (0.25,0) [0|63.75] "temperature:C" Vector__XXX
 SG_ BMS_T_F14 : 40|8@1+ (0.25,0) [0|63.75] "temperature:C" Vector__XXX
 SG_ BMS_T_F13 : 32|8@1+ (0.25,0) [0|63.75] "temperature:C" Vector__XXX
 SG_ BMS_V_F16 : 24|8@1+ (0.01,1.8) [1.8|4.35] "voltage:V" Vector__XXX
 SG_ BMS_V_F15 : 16|8@1+ (0.01,1.8) [1.8|4.35] "voltage:V" Vector__XXX
 SG_ BMS_V_F14 : 8|8@1+ (0.01,1.8) [1.8|4.35] "voltage:V" Vector__XXX
 SG_ BMS_V_F13 : 0|8@1+ (0.01,1.8) [1.8|4.35] "voltage:V" Vector__XXX

BO_ 232 M232_BMS_F9_F12: 8 BMS
 SG_ BMS_T_F12 : 56|8@1+ (0.25,0) [0|63.75] "temperature:C" Vector__XXX
 SG_ BMS_T_F11 : 48|8@1+ (0.25,0) [0|63.75] "temperature:C" Vector__XXX
 SG_ BMS_T_F10 : 40|8@1+ (0.25,0) [0|63.75] "temperature:C" Vector__XXX
 SG_ BMS_T_F9 : 32|8@1+ (0.25,0) [0|63.75] "temperature:C" Vector__XXX
 SG_ BMS_V_F12 : 24|8@1+ (0.01,1.8) [1.8|4.35] "voltage:V" Vector__XXX
 SG_ BMS_V_F11 : 16|8@1+ (0.01,1.8) [1.8|4.35] "voltage:V" Vector__XXX
 SG_ BMS_V_F10 : 8|8@1+ (0.01,1.8) [1.8|4.35] "voltage:V" Vector__XXX
 SG_ BMS_V_F9 : 0|8@1+ (0.01,1.8) [1.8|4.35] "voltage:V" Vector__XXX

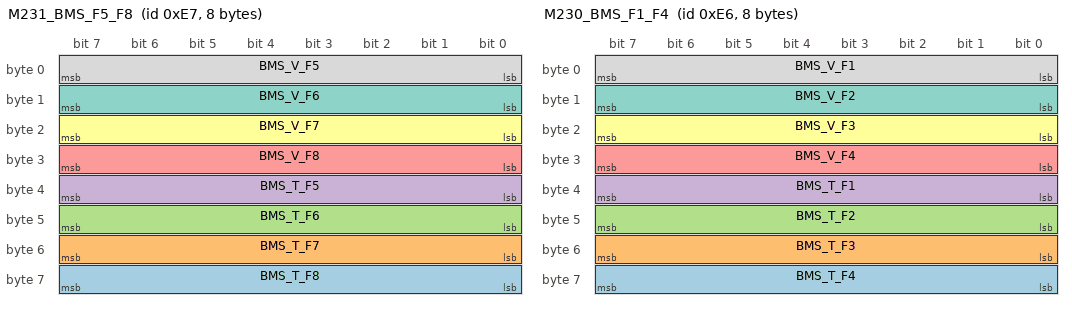
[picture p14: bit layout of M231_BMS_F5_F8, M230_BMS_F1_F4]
BO_ 231 M231_BMS_F5_F8: 8 BMS
 SG_ BMS_T_F8 : 56|8@1+ (0.25,0) [0|63.75] "temperature:C" Vector__XXX
 SG_ BMS_T_F7 : 48|8@1+ (0.25,0) [0|63.75] "temperature:C" Vector__XXX
 SG_ BMS_T_F6 : 40|8@1+ (0.25,0) [0|63.75] "temperature:C" Vector__XXX
 SG_ BMS_T_F5 : 32|8@1+ (0.25,0) [0|63.75] "temperature:C" Vector__XXX
 SG_ BMS_V_F8 : 24|8@1+ (0.01,1.8) [1.8|4.35] "voltage:V" Vector__XXX
 SG_ BMS_V_F7 : 16|8@1+ (0.01,1.8) [1.8|4.35] "voltage:V" Vector__XXX
 SG_ BMS_V_F6 : 8|8@1+ (0.01,1.8) [1.8|4.35] "voltage:V" Vector__XXX
 SG_ BMS_V_F5 : 0|8@1+ (0.01,1.8) [1.8|4.35] "voltage:V" Vector__XXX

BO_ 230 M230_BMS_F1_F4: 8 BMS
 SG_ BMS_T_F4 : 56|8@1+ (0.25,0) [0|63.75] "temperature:C" Vector__XXX
 SG_ BMS_T_F3 : 48|8@1+ (0.25,0) [0|63.75] "temperature:C" Vector__XXX
 SG_ BMS_T_F2 : 40|8@1+ (0.25,0) [0|63.75] "temperature:C" Vector__XXX
 SG_ BMS_T_F1 : 32|8@1+ (0.25,0) [0|63.75] "temperature:C" Vector__XXX
 SG_ BMS_V_F4 : 24|8@1+ (0.01,1.8) [1.8|4.35] "voltage:V" Vector__XXX
 SG_ BMS_V_F3 : 16|8@1+ (0.01,1.8) [1.8|4.35] "voltage:V" Vector__XXX
 SG_ BMS_V_F2 : 8|8@1+ (0.01,1.8) [1.8|4.35] "voltage:V" Vector__XXX
 SG_ BMS_V_F1 : 0|8@1+ (0.01,1.8) [1.8|4.35] "voltage:V" Vector__XXX

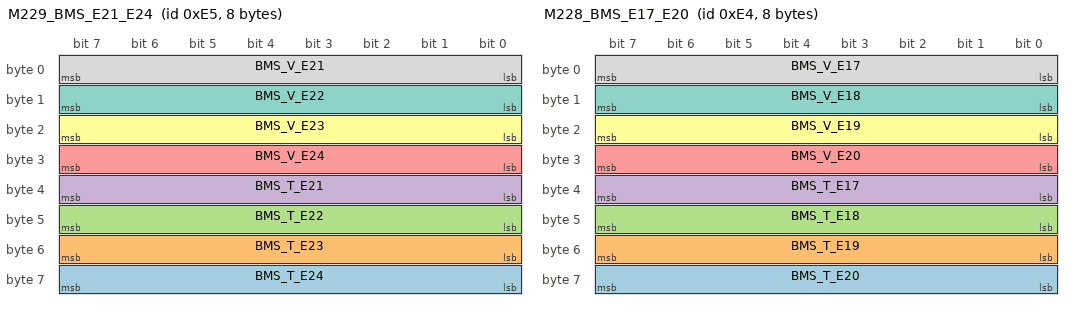
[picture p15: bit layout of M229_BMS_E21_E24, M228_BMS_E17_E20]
BO_ 229 M229_BMS_E21_E24: 8 BMS
 SG_ BMS_T_E24 : 56|8@1+ (0.25,0) [0|63.75] "temperature:C" Vector__XXX
 SG_ BMS_T_E23 : 48|8@1+ (0.25,0) [0|63.75] "temperature:C" Vector__XXX
 SG_ BMS_T_E22 : 40|8@1+ (0.25,0) [0|63.75] "temperature:C" Vector__XXX
 SG_ BMS_T_E21 : 32|8@1+ (0.25,0) [0|63.75] "temperature:C" Vector__XXX
 SG_ BMS_V_E24 : 24|8@1+ (0.01,1.8) [1.8|4.35] "voltage:V" Vector__XXX
 SG_ BMS_V_E23 : 16|8@1+ (0.01,1.8) [1.8|4.35] "voltage:V" Vector__XXX
 SG_ BMS_V_E22 : 8|8@1+ (0.01,1.8) [1.8|4.35] "voltage:V" Vector__XXX
 SG_ BMS_V_E21 : 0|8@1+ (0.01,1.8) [1.8|4.35] "voltage:V" Vector__XXX

BO_ 228 M228_BMS_E17_E20: 8 BMS
 SG_ BMS_T_E20 : 56|8@1+ (0.25,0) [0|63.75] "temperature:C" Vector__XXX
 SG_ BMS_T_E19 : 48|8@1+ (0.25,0) [0|63.75] "temperature:C" Vector__XXX
 SG_ BMS_T_E18 : 40|8@1+ (0.25,0) [0|63.75] "temperature:C" Vector__XXX
 SG_ BMS_T_E17 : 32|8@1+ (0.25,0) [0|63.75] "temperature:C" Vector__XXX
 SG_ BMS_V_E20 : 24|8@1+ (0.01,1.8) [1.8|4.35] "voltage:V" Vector__XXX
 SG_ BMS_V_E19 : 16|8@1+ (0.01,1.8) [1.8|4.35] "voltage:V" Vector__XXX
 SG_ BMS_V_E18 : 8|8@1+ (0.01,1.8) [1.8|4.35] "voltage:V" Vector__XXX
 SG_ BMS_V_E17 : 0|8@1+ (0.01,1.8) [1.8|4.35] "voltage:V" Vector__XXX

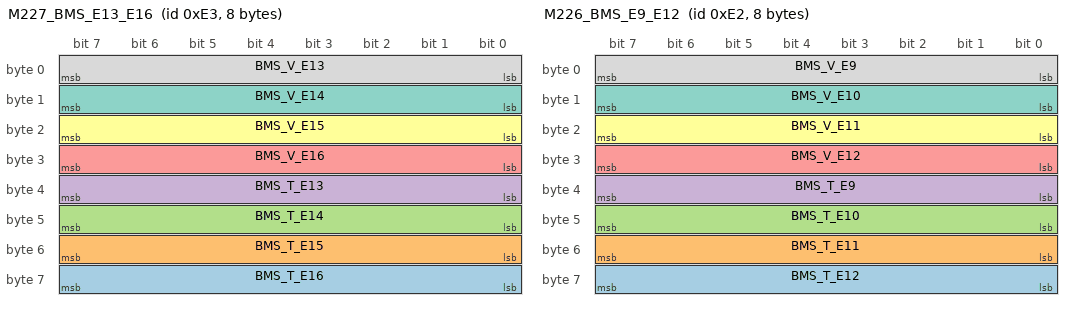
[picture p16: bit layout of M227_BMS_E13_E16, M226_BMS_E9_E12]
BO_ 227 M227_BMS_E13_E16: 8 BMS
 SG_ BMS_T_E16 : 56|8@1+ (0.25,0) [0|63.75] "temperature:C" Vector__XXX
 SG_ BMS_T_E15 : 48|8@1+ (0.25,0) [0|63.75] "temperature:C" Vector__XXX
 SG_ BMS_T_E14 : 40|8@1+ (0.25,0) [0|63.75] "temperature:C" Vector__XXX
 SG_ BMS_T_E13 : 32|8@1+ (0.25,0) [0|63.75] "temperature:C" Vector__XXX
 SG_ BMS_V_E16 : 24|8@1+ (0.01,1.8) [1.8|4.35] "voltage:V" Vector__XXX
 SG_ BMS_V_E15 : 16|8@1+ (0.01,1.8) [1.8|4.35] "voltage:V" Vector__XXX
 SG_ BMS_V_E14 : 8|8@1+ (0.01,1.8) [1.8|4.35] "voltage:V" Vector__XXX
 SG_ BMS_V_E13 : 0|8@1+ (0.01,1.8) [1.8|4.35] "voltage:V" Vector__XXX

BO_ 226 M226_BMS_E9_E12: 8 BMS
 SG_ BMS_T_E12 : 56|8@1+ (0.25,0) [0|63.75] "temperature:C" Vector__XXX
 SG_ BMS_T_E11 : 48|8@1+ (0.25,0) [0|63.75] "temperature:C" Vector__XXX
 SG_ BMS_T_E10 : 40|8@1+ (0.25,0) [0|63.75] "temperature:C" Vector__XXX
 SG_ BMS_T_E9 : 32|8@1+ (0.25,0) [0|63.75] "temperature:C" Vector__XXX
 SG_ BMS_V_E12 : 24|8@1+ (0.01,1.8) [1.8|4.35] "voltage:V" Vector__XXX
 SG_ BMS_V_E11 : 16|8@1+ (0.01,1.8) [1.8|4.35] "voltage:V" Vector__XXX
 SG_ BMS_V_E10 : 8|8@1+ (0.01,1.8) [1.8|4.35] "voltage:V" Vector__XXX
 SG_ BMS_V_E9 : 0|8@1+ (0.01,1.8) [1.8|4.35] "voltage:V" Vector__XXX

BO_ 225 M225_BMS_E5_E8: 8 BMS
 SG_ BMS_T_E8 : 56|8@1+ (0.25,0) [0|63.75] "temperature:C" Vector__XXX
 SG_ BMS_T_E7 : 48|8@1+ (0.25,0) [0|63.75] "temperature:C" Vector__XXX
 SG_ BMS_T_E6 : 40|8@1+ (0.25,0) [0|63.75] "temperature:C" Vector__XXX
 SG_ BMS_T_E5 : 32|8@1+ (0.25,0) [0|63.75] "temperature:C" Vector__XXX
 SG_ BMS_V_E8 : 24|8@1+ (0.01,1.8) [1.8|4.35] "voltage:V" Vector__XXX
 SG_ BMS_V_E7 : 16|8@1+ (0.01,1.8) [1.8|4.35] "voltage:V" Vector__XXX
 SG_ BMS_V_E6 : 8|8@1+ (0.01,1.8) [1.8|4.35] "voltage:V" Vector__XXX
 SG_ BMS_V_E5 : 0|8@1+ (0.01,1.8) [1.8|4.35] "voltage:V" Vector__XXX

BO_ 224 M224_BMS_E1_E4: 8 BMS
 SG_ BMS_T_E4 : 56|8@1+ (0.25,0) [0|63.75] "temperature:C" Vector__XXX
 SG_ BMS_T_E3 : 48|8@1+ (0.25,0) [0|63.75] "temperature:C" Vector__XXX
 SG_ BMS_T_E2 : 40|8@1+ (0.25,0) [0|63.75] "temperature:C" Vector__XXX
 SG_ BMS_T_E1 : 32|8@1+ (0.25,0) [0|63.75] "temperature:C" Vector__XXX
 SG_ BMS_V_E4 : 24|8@1+ (0.01,1.8) [1.8|4.35] "voltage:V" Vector__XXX
 SG_ BMS_V_E3 : 16|8@1+ (0.01,1.8) [1.8|4.35] "voltage:V" Vector__XXX
 SG_ BMS_V_E2 : 8|8@1+ (0.01,1.8) [1.8|4.35] "voltage:V" Vector__XXX
 SG_ BMS_V_E1 : 0|8@1+ (0.01,1.8) [1.8|4.35] "voltage:V" Vector__XXX

BO_ 223 M223_BMS_D21_D24: 8 BMS
 SG_ BMS_T_D24 : 56|8@1+ (0.25,0) [0|63.75] "temperature:C" Vector__XXX
 SG_ BMS_T_D23 : 48|8@1+ (0.25,0) [0|63.75] "temperature:C" Vector__XXX
 SG_ BMS_T_D22 : 40|8@1+ (0.25,0) [0|63.75] "temperature:C" Vector__XXX
 SG_ BMS_T_D21 : 32|8@1+ (0.25,0) [0|63.75] "temperature:C" Vector__XXX
 SG_ BMS_V_D24 : 24|8@1+ (0.01,1.8) [1.8|4.35] "voltage:V" Vector__XXX
 SG_ BMS_V_D23 : 16|8@1+ (0.01,1.8) [1.8|4.35] "voltage:V" Vector__XXX
 SG_ BMS_V_D22 : 8|8@1+ (0.01,1.8) [1.8|4.35] "voltage:V" Vector__XXX
 SG_ BMS_V_D21 : 0|8@1+ (0.01,1.8) [1.8|4.35] "voltage:V" Vector__XXX

BO_ 222 M222_BMS_D17_D20: 8 BMS
 SG_ BMS_T_D20 : 56|8@1+ (0.25,0) [0|63.75] "temperature:C" Vector__XXX
 SG_ BMS_T_D19 : 48|8@1+ (0.25,0) [0|63.75] "temperature:C" Vector__XXX
 SG_ BMS_T_D18 : 40|8@1+ (0.25,0) [0|63.75] "temperature:C" Vector__XXX
 SG_ BMS_T_D17 : 32|8@1+ (0.25,0) [0|63.75] "temperature:C" Vector__XXX
 SG_ BMS_V_D20 : 24|8@1+ (0.01,1.8) [1.8|4.35] "voltage:V" Vector__XXX
 SG_ BMS_V_D19 : 16|8@1+ (0.01,1.8) [1.8|4.35] "voltage:V" Vector__XXX
 SG_ BMS_V_D18 : 8|8@1+ (0.01,1.8) [1.8|4.35] "voltage:V" Vector__XXX
 SG_ BMS_V_D17 : 0|8@1+ (0.01,1.8) [1.8|4.35] "voltage:V" Vector__XXX

BO_ 221 M221_BMS_D13_D16: 8 BMS
 SG_ BMS_T_D16 : 56|8@1+ (0.25,0) [0|63.75] "temperature:C" Vector__XXX
 SG_ BMS_T_D15 : 48|8@1+ (0.25,0) [0|63.75] "temperature:C" Vector__XXX
 SG_ BMS_T_D14 : 40|8@1+ (0.25,0) [0|63.75] "temperature:C" Vector__XXX
 SG_ BMS_T_D13 : 32|8@1+ (0.25,0) [0|63.75] "temperature:C" Vector__XXX
 SG_ BMS_V_D16 : 24|8@1+ (0.01,1.8) [1.8|4.35] "voltage:V" Vector__XXX
 SG_ BMS_V_D15 : 16|8@1+ (0.01,1.8) [1.8|4.35] "voltage:V" Vector__XXX
 SG_ BMS_V_D14 : 8|8@1+ (0.01,1.8) [1.8|4.35] "voltage:V" Vector__XXX
 SG_ BMS_V_D13 : 0|8@1+ (0.01,1.8) [1.8|4.35] "voltage:V" Vector__XXX

BO_ 220 M220_BMS_D9_D12: 8 BMS
 SG_ BMS_T_D12 : 56|8@1+ (0.25,0) [0|63.75] "temperature:C" Vector__XXX
 SG_ BMS_T_D11 : 48|8@1+ (0.25,0) [0|63.75] "temperature:C" Vector__XXX
 SG_ BMS_T_D10 : 40|8@1+ (0.25,0) [0|63.75] "temperature:C" Vector__XXX
 SG_ BMS_T_D9 : 32|8@1+ (0.25,0) [0|63.75] "temperature:C" Vector__XXX
 SG_ BMS_V_D12 : 24|8@1+ (0.01,1.8) [1.8|4.35] "voltage:V" Vector__XXX
 SG_ BMS_V_D11 : 16|8@1+ (0.01,1.8) [1.8|4.35] "voltage:V" Vector__XXX
 SG_ BMS_V_D10 : 8|8@1+ (0.01,1.8) [1.8|4.35] "voltage:V" Vector__XXX
 SG_ BMS_V_D9 : 0|8@1+ (0.01,1.8) [1.8|4.35] "voltage:V" Vector__XXX

BO_ 219 M219_BMS_D5_D8: 8 BMS
 SG_ BMS_T_D8 : 56|8@1+ (0.25,0) [0|63.75] "temperature:C" Vector__XXX
 SG_ BMS_T_D7 : 48|8@1+ (0.25,0) [0|63.75] "temperature:C" Vector__XXX
 SG_ BMS_T_D6 : 40|8@1+ (0.25,0) [0|63.75] "temperature:C" Vector__XXX
 SG_ BMS_T_D5 : 32|8@1+ (0.25,0) [0|63.75] "temperature:C" Vector__XXX
 SG_ BMS_V_D8 : 24|8@1+ (0.01,1.8) [1.8|4.35] "voltage:V" Vector__XXX
 SG_ BMS_V_D7 : 16|8@1+ (0.01,1.8) [1.8|4.35] "voltage:V" Vector__XXX
 SG_ BMS_V_D6 : 8|8@1+ (0.01,1.8) [1.8|4.35] "voltage:V" Vector__XXX
 SG_ BMS_V_D5 : 0|8@1+ (0.01,1.8) [1.8|4.35] "voltage:V" Vector__XXX

BO_ 218 M218_BMS_D1_D4: 8 BMS
 SG_ BMS_T_D4 : 56|8@1+ (0.25,0) [0|63.75] "temperature:C" Vector__XXX
 SG_ BMS_T_D3 : 48|8@1+ (0.25,0) [0|63.75] "temperature:C" Vector__XXX
 SG_ BMS_T_D2 : 40|8@1+ (0.25,0) [0|63.75] "temperature:C" Vector__XXX
 SG_ BMS_T_D1 : 32|8@1+ (0.25,0) [0|63.75] "temperature:C" Vector__XXX
 SG_ BMS_V_D4 : 24|8@1+ (0.01,1.8) [1.8|4.35] "voltage:V" Vector__XXX
 SG_ BMS_V_D3 : 16|8@1+ (0.01,1.8) [1.8|4.35] "voltage:V" Vector__XXX
 SG_ BMS_V_D2 : 8|8@1+ (0.01,1.8) [1.8|4.35] "voltage:V" Vector__XXX
 SG_ BMS_V_D1 : 0|8@1+ (0.01,1.8) [1.8|4.35] "voltage:V" Vector__XXX

BO_ 217 M217_BMS_C21_C24: 8 BMS
 SG_ BMS_T_C24 : 56|8@1+ (0.25,0) [0|63.75] "temperature:C" Vector__XXX
 SG_ BMS_T_C23 : 48|8@1+ (0.25,0) [0|63.75] "temperature:C" Vector__XXX
 SG_ BMS_T_C22 : 40|8@1+ (0.25,0) [0|63.75] "temperature:C" Vector__XXX
 SG_ BMS_T_C21 : 32|8@1+ (0.25,0) [0|63.75] "temperature:C" Vector__XXX
 SG_ BMS_V_C24 : 24|8@1+ (0.01,1.8) [1.8|4.35] "voltage:V" Vector__XXX
 SG_ BMS_V_C23 : 16|8@1+ (0.01,1.8) [1.8|4.35] "voltage:V" Vector__XXX
 SG_ BMS_V_C22 : 8|8@1+ (0.01,1.8) [1.8|4.35] "voltage:V" Vector__XXX
 SG_ BMS_V_C21 : 0|8@1+ (0.01,1.8) [1.8|4.35] "voltage:V" Vector__XXX

BO_ 216 M216_BMS_C17_C20: 8 BMS
 SG_ BMS_T_C20 : 56|8@1+ (0.25,0) [0|63.75] "temperature:C" Vector__XXX
 SG_ BMS_T_C19 : 48|8@1+ (0.25,0) [0|63.75] "temperature:C" Vector__XXX
 SG_ BMS_T_C18 : 40|8@1+ (0.25,0) [0|63.75] "temperature:C" Vector__XXX
 SG_ BMS_T_C17 : 32|8@1+ (0.25,0) [0|63.75] "temperature:C" Vector__XXX
 SG_ BMS_V_C20 : 24|8@1+ (0.01,1.8) [1.8|4.35] "voltage:V" Vector__XXX
 SG_ BMS_V_C19 : 16|8@1+ (0.01,1.8) [1.8|4.35] "voltage:V" Vector__XXX
 SG_ BMS_V_C18 : 8|8@1+ (0.01,1.8) [1.8|4.35] "voltage:V" Vector__XXX
 SG_ BMS_V_C17 : 0|8@1+ (0.01,1.8) [1.8|4.35] "voltage:V" Vector__XXX

BO_ 215 M215_BMS_C13_C16: 8 BMS
 SG_ BMS_T_C16 : 56|8@1+ (0.25,0) [0|63.75] "temperature:C" Vector__XXX
 SG_ BMS_T_C15 : 48|8@1+ (0.25,0) [0|63.75] "temperature:C" Vector__XXX
 SG_ BMS_T_C14 : 40|8@1+ (0.25,0) [0|63.75] "temperature:C" Vector__XXX
 SG_ BMS_T_C13 : 32|8@1+ (0.25,0) [0|63.75] "temperature:C" Vector__XXX
 SG_ BMS_V_C16 : 24|8@1+ (0.01,1.8) [1.8|4.35] "voltage:V" Vector__XXX
 SG_ BMS_V_C15 : 16|8@1+ (0.01,1.8) [1.8|4.35] "voltage:V" Vector__XXX
 SG_ BMS_V_C14 : 8|8@1+ (0.01,1.8) [1.8|4.35] "voltage:V" Vector__XXX
 SG_ BMS_V_C13 : 0|8@1+ (0.01,1.8) [1.8|4.35] "voltage:V" Vector__XXX

BO_ 214 M214_BMS_C9_C12: 8 BMS
 SG_ BMS_T_C12 : 56|8@1+ (0.25,0) [0|63.75] "temperature:C" Vector__XXX
 SG_ BMS_T_C11 : 48|8@1+ (0.25,0) [0|63.75] "temperature:C" Vector__XXX
 SG_ BMS_T_C10 : 40|8@1+ (0.25,0) [0|63.75] "temperature:C" Vector__XXX
 SG_ BMS_T_C9 : 32|8@1+ (0.25,0) [0|63.75] "temperature:C" Vector__XXX
 SG_ BMS_V_C12 : 24|8@1+ (0.01,1.8) [1.8|4.35] "voltage:V" Vector__XXX
 SG_ BMS_V_C11 : 16|8@1+ (0.01,1.8) [1.8|4.35] "voltage:V" Vector__XXX
 SG_ BMS_V_C10 : 8|8@1+ (0.01,1.8) [1.8|4.35] "voltage:V" Vector__XXX
 SG_ BMS_V_C9 : 0|8@1+ (0.01,1.8) [1.8|4.35] "voltage:V" Vector__XXX

BO_ 213 M213_BMS_C5_C8: 8 BMS
 SG_ BMS_T_C8 : 56|8@1+ (0.25,0) [0|63.75] "temperature:C" Vector__XXX
 SG_ BMS_T_C7 : 48|8@1+ (0.25,0) [0|63.75] "temperature:C" Vector__XXX
 SG_ BMS_T_C6 : 40|8@1+ (0.25,0) [0|63.75] "temperature:C" Vector__XXX
 SG_ BMS_T_C5 : 32|8@1+ (0.25,0) [0|63.75] "temperature:C" Vector__XXX
 SG_ BMS_V_C8 : 24|8@1+ (0.01,1.8) [1.8|4.35] "voltage:V" Vector__XXX
 SG_ BMS_V_C7 : 16|8@1+ (0.01,1.8) [1.8|4.35] "voltage:V" Vector__XXX
 SG_ BMS_V_C6 : 8|8@1+ (0.01,1.8) [1.8|4.35] "voltage:V" Vector__XXX
 SG_ BMS_V_C5 : 0|8@1+ (0.01,1.8) [1.8|4.35] "voltage:V" Vector__XXX

BO_ 212 M212_BMS_C1_C4: 8 BMS
 SG_ BMS_T_C4 : 56|8@1+ (0.25,0) [0|63.75] "temperature:C" Vector__XXX
 SG_ BMS_T_C3 : 48|8@1+ (0.25,0) [0|63.75] "temperature:C" Vector__XXX
 SG_ BMS_T_C2 : 40|8@1+ (0.25,0) [0|63.75] "temperature:C" Vector__XXX
 SG_ BMS_T_C1 : 32|8@1+ (0.25,0) [0|63.75] "temperature:C" Vector__XXX
 SG_ BMS_V_C4 : 24|8@1+ (0.01,1.8) [1.8|4.35] "voltage:V" Vector__XXX
 SG_ BMS_V_C3 : 16|8@1+ (0.01,1.8) [1.8|4.35] "voltage:V" Vector__XXX
 SG_ BMS_V_C2 : 8|8@1+ (0.01,1.8) [1.8|4.35] "voltage:V" Vector__XXX
 SG_ BMS_V_C1 : 0|8@1+ (0.01,1.8) [1.8|4.35] "voltage:V" Vector__XXX

BO_ 211 M211_BMS_B21_B24: 8 BMS
 SG_ BMS_T_B24 : 56|8@1+ (0.25,0) [0|63.75] "temperature:C" Vector__XXX
 SG_ BMS_T_B23 : 48|8@1+ (0.25,0) [0|63.75] "temperature:C" Vector__XXX
 SG_ BMS_T_B22 : 40|8@1+ (0.25,0) [0|63.75] "temperature:C" Vector__XXX
 SG_ BMS_T_B21 : 32|8@1+ (0.25,0) [0|63.75] "temperature:C" Vector__XXX
 SG_ BMS_V_B24 : 24|8@1+ (0.01,1.8) [1.8|4.35] "voltage:V" Vector__XXX
 SG_ BMS_V_B23 : 16|8@1+ (0.01,1.8) [1.8|4.35] "voltage:V" Vector__XXX
 SG_ BMS_V_B22 : 8|8@1+ (0.01,1.8) [1.8|4.35] "voltage:V" Vector__XXX
 SG_ BMS_V_B21 : 0|8@1+ (0.01,1.8) [1.8|4.35] "voltage:V" Vector__XXX

BO_ 210 M210_BMS_B17_B20: 8 BMS
 SG_ BMS_T_B20 : 56|8@1+ (0.25,0) [0|63.75] "temperature:C" Vector__XXX
 SG_ BMS_T_B19 : 48|8@1+ (0.25,0) [0|63.75] "temperature:C" Vector__XXX
 SG_ BMS_T_B18 : 40|8@1+ (0.25,0) [0|63.75] "temperature:C" Vector__XXX
 SG_ BMS_T_B17 : 32|8@1+ (0.25,0) [0|63.75] "temperature:C" Vector__XXX
 SG_ BMS_V_B20 : 24|8@1+ (0.01,1.8) [1.8|4.35] "voltage:V" Vector__XXX
 SG_ BMS_V_B19 : 16|8@1+ (0.01,1.8) [1.8|4.35] "voltage:V" Vector__XXX
 SG_ BMS_V_B18 : 8|8@1+ (0.01,1.8) [1.8|4.35] "voltage:V" Vector__XXX
 SG_ BMS_V_B17 : 0|8@1+ (0.01,1.8) [1.8|4.35] "voltage:V" Vector__XXX

BO_ 209 M209_BMS_B13_B16: 8 BMS
 SG_ BMS_T_B16 : 56|8@1+ (0.25,0) [0|63.75] "temperature:C" Vector__XXX
 SG_ BMS_T_B15 : 48|8@1+ (0.25,0) [0|63.75] "temperature:C" Vector__XXX
 SG_ BMS_T_B14 : 40|8@1+ (0.25,0) [0|63.75] "temperature:C" Vector__XXX
 SG_ BMS_T_B13 : 32|8@1+ (0.25,0) [0|63.75] "temperature:C" Vector__XXX
 SG_ BMS_V_B16 : 24|8@1+ (0.01,1.8) [1.8|4.35] "voltage:V" Vector__XXX
 SG_ BMS_V_B15 : 16|8@1+ (0.01,1.8) [1.8|4.35] "voltage:V" Vector__XXX
 SG_ BMS_V_B14 : 8|8@1+ (0.01,1.8) [1.8|4.35] "voltage:V" Vector__XXX
 SG_ BMS_V_B13 : 0|8@1+ (0.01,1.8) [1.8|4.35] "voltage:V" Vector__XXX

BO_ 208 M208_BMS_B9_B12: 8 BMS
 SG_ BMS_T_B12 : 56|8@1+ (0.25,0) [0|63.75] "temperature:C" Vector__XXX
 SG_ BMS_T_B11 : 48|8@1+ (0.25,0) [0|63.75] "temperature:C" Vector__XXX
 SG_ BMS_T_B10 : 40|8@1+ (0.25,0) [0|63.75] "temperature:C" Vector__XXX
 SG_ BMS_T_B9 : 32|8@1+ (0.25,0) [0|63.75] "temperature:C" Vector__XXX
 SG_ BMS_V_B12 : 24|8@1+ (0.01,1.8) [1.8|4.35] "voltage:V" Vector__XXX
 SG_ BMS_V_B11 : 16|8@1+ (0.01,1.8) [1.8|4.35] "voltage:V" Vector__XXX
 SG_ BMS_V_B10 : 8|8@1+ (0.01,1.8) [1.8|4.35] "voltage:V" Vector__XXX
 SG_ BMS_V_B9 : 0|8@1+ (0.01,1.8) [1.8|4.35] "voltage:V" Vector__XXX

BO_ 207 M207_BMS_B5_B8: 8 BMS
 SG_ BMS_T_B8 : 56|8@1+ (0.25,0) [0|63.75] "temperature:C" Vector__XXX
 SG_ BMS_T_B7 : 48|8@1+ (0.25,0) [0|63.75] "temperature:C" Vector__XXX
 SG_ BMS_T_B6 : 40|8@1+ (0.25,0) [0|63.75] "temperature:C" Vector__XXX
 SG_ BMS_T_B5 : 32|8@1+ (0.25,0) [0|63.75] "temperature:C" Vector__XXX
 SG_ BMS_V_B8 : 24|8@1+ (0.01,1.8) [1.8|4.35] "voltage:V" Vector__XXX
 SG_ BMS_V_B7 : 16|8@1+ (0.01,1.8) [1.8|4.35] "voltage:V" Vector__XXX
 SG_ BMS_V_B6 : 8|8@1+ (0.01,1.8) [1.8|4.35] "voltage:V" Vector__XXX
 SG_ BMS_V_B5 : 0|8@1+ (0.01,1.8) [1.8|4.35] "voltage:V" Vector__XXX

BO_ 206 M206_BMS_B1_B4: 8 BMS
 SG_ BMS_T_B4 : 56|8@1+ (0.25,0) [0|63.75] "temperature:C" Vector__XXX
 SG_ BMS_T_B3 : 48|8@1+ (0.25,0) [0|63.75] "temperature:C" Vector__XXX
 SG_ BMS_T_B2 : 40|8@1+ (0.25,0) [0|63.75] "temperature:C" Vector__XXX
 SG_ BMS_T_B1 : 32|8@1+ (0.25,0) [0|63.75] "temperature:C" Vector__XXX
 SG_ BMS_V_B4 : 24|8@1+ (0.01,1.8) [1.8|4.35] "voltage:V" Vector__XXX
 SG_ BMS_V_B3 : 16|8@1+ (0.01,1.8) [1.8|4.35] "voltage:V" Vector__XXX
 SG_ BMS_V_B2 : 8|8@1+ (0.01,1.8) [1.8|4.35] "voltage:V" Vector__XXX
 SG_ BMS_V_B1 : 0|8@1+ (0.01,1.8) [1.8|4.35] "voltage:V" Vector__XXX

BO_ 205 M205_BMS_A21_A24: 8 BMS
 SG_ BMS_T_A24 : 56|8@1+ (0.25,0) [0|63.75] "temperature:C" Vector__XXX
 SG_ BMS_T_A23 : 48|8@1+ (0.25,0) [0|63.75] "temperature:C" Vector__XXX
 SG_ BMS_T_A22 : 40|8@1+ (0.25,0) [0|63.75] "temperature:C" Vector__XXX
 SG_ BMS_T_A21 : 32|8@1+ (0.25,0) [0|63.75] "temperature:C" Vector__XXX
 SG_ BMS_V_A24 : 24|8@1+ (0.01,1.8) [1.8|4.35] "voltage:V" Vector__XXX
 SG_ BMS_V_A23 : 16|8@1+ (0.01,1.8) [1.8|4.35] "voltage:V" Vector__XXX
 SG_ BMS_V_A22 : 8|8@1+ (0.01,1.8) [1.8|4.35] "voltage:V" Vector__XXX
 SG_ BMS_V_A21 : 0|8@1+ (0.01,1.8) [1.8|4.35] "voltage:V" Vector__XXX

BO_ 204 M204_BMS_A17_A20: 8 BMS
 SG_ BMS_T_A20 : 56|8@1+ (0.25,0) [0|63.75] "temperature:C" Vector__XXX
 SG_ BMS_T_A19 : 48|8@1+ (0.25,0) [0|63.75] "temperature:C" Vector__XXX
 SG_ BMS_T_A18 : 40|8@1+ (0.25,0) [0|63.75] "temperature:C" Vector__XXX
 SG_ BMS_T_A17 : 32|8@1+ (0.25,0) [0|63.75] "temperature:C" Vector__XXX
 SG_ BMS_V_A20 : 24|8@1+ (0.01,1.8) [1.8|4.35] "voltage:V" Vector__XXX
 SG_ BMS_V_A19 : 16|8@1+ (0.01,1.8) [1.8|4.35] "voltage:V" Vector__XXX
 SG_ BMS_V_A18 : 8|8@1+ (0.01,1.8) [1.8|4.35] "voltage:V" Vector__XXX
 SG_ BMS_V_A17 : 0|8@1+ (0.01,1.8) [1.8|4.35] "voltage:V" Vector__XXX

BO_ 203 M203_BMS_A13_A16: 8 BMS
 SG_ BMS_T_A16 : 56|8@1+ (0.25,0) [0|63.75] "temperature:C" Vector__XXX
 SG_ BMS_T_A15 : 48|8@1+ (0.25,0) [0|63.75] "temperature:C" Vector__XXX
 SG_ BMS_T_A14 : 40|8@1+ (0.25,0) [0|63.75] "temperature:C" Vector__XXX
 SG_ BMS_T_A13 : 32|8@1+ (0.25,0) [0|63.75] "temperature:C" Vector__XXX
 SG_ BMS_V_A16 : 24|8@1+ (0.01,1.8) [1.8|4.35] "voltage:V" Vector__XXX
 SG_ BMS_V_A15 : 16|8@1+ (0.01,1.8) [1.8|4.35] "voltage:V" Vector__XXX
 SG_ BMS_V_A14 : 8|8@1+ (0.01,1.8) [1.8|4.35] "voltage:V" Vector__XXX
 SG_ BMS_V_A13 : 0|8@1+ (0.01,1.8) [1.8|4.35] "voltage:V" Vector__XXX

BO_ 202 M202_BMS_A9_A12: 8 BMS
 SG_ BMS_T_A12 : 56|8@1+ (0.25,0) [0|63.75] "temperature:C" Vector__XXX
 SG_ BMS_T_A11 : 48|8@1+ (0.25,0) [0|63.75] "temperature:C" Vector__XXX
 SG_ BMS_T_A10 : 40|8@1+ (0.25,0) [0|63.75] "temperature:C" Vector__XXX
 SG_ BMS_T_A9 : 32|8@1+ (0.25,0) [0|63.75] "temperature:C" Vector__XXX
 SG_ BMS_V_A12 : 24|8@1+ (0.01,1.8) [1.8|4.35] "voltage:V" Vector__XXX
 SG_ BMS_V_A11 : 16|8@1+ (0.01,1.8) [1.8|4.35] "voltage:V" Vector__XXX
 SG_ BMS_V_A10 : 8|8@1+ (0.01,1.8) [1.8|4.35] "voltage:V" Vector__XXX
 SG_ BMS_V_A9 : 0|8@1+ (0.01,1.8) [1.8|4.35] "voltage:V" Vector__XXX

BO_ 201 M201_BMS_A5_A8: 8 BMS
 SG_ BMS_T_A8 : 56|8@1+ (0.25,0) [0|63.75] "temperature:C" Vector__XXX
 SG_ BMS_T_A7 : 48|8@1+ (0.25,0) [0|63.75] "temperature:C" Vector__XXX
 SG_ BMS_T_A6 : 40|8@1+ (0.25,0) [0|63.75] "temperature:C" Vector__XXX
 SG_ BMS_T_A5 : 32|8@1+ (0.25,0) [0|63.75] "temperature:C" Vector__XXX
 SG_ BMS_V_A8 : 24|8@1+ (0.01,1.8) [1.8|4.35] "voltage:V" Vector__XXX
 SG_ BMS_V_A7 : 16|8@1+ (0.01,1.8) [1.8|4.35] "voltage:V" Vector__XXX
 SG_ BMS_V_A6 : 8|8@1+ (0.01,1.8) [1.8|4.35] "voltage:V" Vector__XXX
 SG_ BMS_V_A5 : 0|8@1+ (0.01,1.8) [1.8|4.35] "voltage:V" Vector__XXX

BO_ 200 M200_BMS_A1_A4: 8 BMS
 SG_ BMS_T_A4 : 56|8@1+ (0.25,0) [0|63.75] "temperature:C" Vector__XXX
 SG_ BMS_T_A3 : 48|8@1+ (0.25,0) [0|63.75] "temperature:C" Vector__XXX
 SG_ BMS_T_A2 : 40|8@1+ (0.25,0) [0|63.75] "temperature:C" Vector__XXX
 SG_ BMS_T_A1 : 32|8@1+ (0.25,0) [0|63.75] "temperature:C" Vector__XXX
 SG_ BMS_V_A4 : 24|8@1+ (0.01,1.8) [1.8|4.35] "voltage:V" Vector__XXX
 SG_ BMS_V_A3 : 16|8@1+ (0.01,1.8) [1.8|4.35] "voltage:V" Vector__XXX
 SG_ BMS_V_A2 : 8|8@1+ (0.01,1.8) [1.8|4.35] "voltage:V" Vector__XXX
 SG_ BMS_V_A1 : 0|8@1+ (0.01,1.8) [1.8|4.35] "voltage:V" Vector__XXX

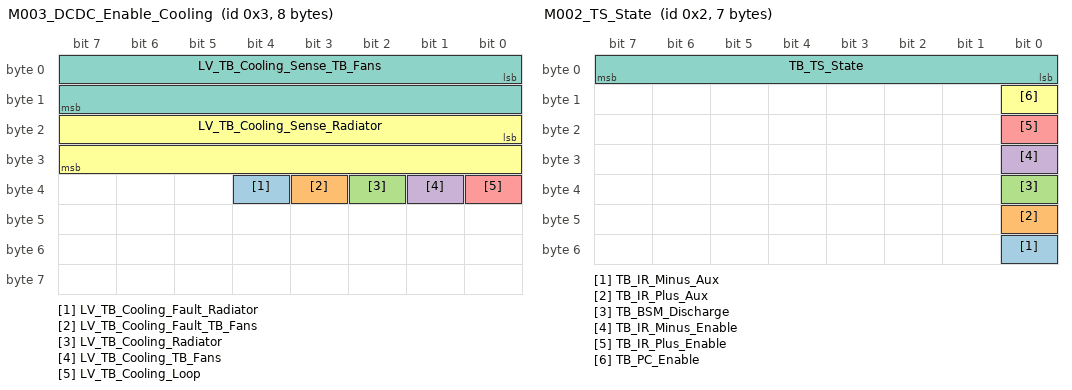
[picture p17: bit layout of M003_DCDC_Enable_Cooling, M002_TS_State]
BO_ 3 M003_DCDC_Enable_Cooling: 8 LV
 SG_ LV_TB_Cooling_Fault_Radiator : 36|1@1+ (1,0) [0|1] "" Vector__XXX
 SG_ LV_TB_Cooling_Fault_TB_Fans : 35|1@1+ (1,0) [0|1] "" Vector__XXX
 SG_ LV_TB_Cooling_Radiator : 34|1@1+ (1,0) [0|1] "" Vector__XXX
 SG_ LV_TB_Cooling_TB_Fans : 33|1@1+ (1,0) [0|1] "" Vector__XXX
 SG_ LV_TB_Cooling_Loop : 32|1@1+ (1,0) [0|1] "" Vector__XXX
 SG_ LV_TB_Cooling_Sense_Radiator : 16|16@1- (0.01,0) [-327.68|327.67] "" Vector__XXX
 SG_ LV_TB_Cooling_Sense_TB_Fans : 0|16@1- (0.01,0) [-327.68|327.67] "" Vector__XXX

BO_ 2 M002_TS_State: 7 TB
 SG_ TB_IR_Minus_Aux : 48|1@1+ (1,0) [0|1] "" Vector__XXX
 SG_ TB_IR_Plus_Aux : 40|1@1+ (1,0) [0|1] "" Vector__XXX
 SG_ TB_BSM_Discharge : 32|1@1+ (1,0) [0|1] "" Vector__XXX
 SG_ TB_IR_Minus_Enable : 24|1@1+ (1,0) [0|1] "" Vector__XXX
 SG_ TB_IR_Plus_Enable : 16|1@1+ (1,0) [0|1] "" Vector__XXX
 SG_ TB_PC_Enable : 8|1@1+ (1,0) [0|1] "" Vector__XXX
 SG_ TB_TS_State : 0|8@1- (1,0) [0|0] ""  LV

BO_ 1 M001_Vehicle_State: 1 LV
 SG_ LV_Vehicle_State : 0|8@1- (1,0) [0|0] "" Vector__XXX

BO_ 402 M402_Brakes_Faults_Display: 8 LV
 SG_ LV_Momentary_Both_Pedals : 63|1@1+ (1,0) [0|1] "" Vector__XXX
 SG_ LV_Momentary_APPS_Implausibility : 62|1@1+ (1,0) [0|1] "" Vector__XXX
 SG_ LV_Momentary_BPT_Upper : 61|1@1+ (1,0) [0|1] "" Vector__XXX
 SG_ LV_Momentary_BPT_Lower : 60|1@1+ (1,0) [0|1] "" Vector__XXX
 SG_ LV_Momentary_APPS2_Upper : 59|1@1+ (1,0) [0|1] "" Vector__XXX
 SG_ LV_Momentary_APPS2_Lower : 58|1@1+ (1,0) [0|1] "" Vector__XXX
 SG_ LV_Momentary_APPS1_Upper : 57|1@1+ (1,0) [0|1] "" Vector__XXX
 SG_ LV_Momentary_APPS1_Lower : 56|1@1+ (1,0) [0|1] "" Vector__XXX
 SG_ LV_Fault_Both_Pedals : 55|1@1+ (1,0) [0|1] "" Vector__XXX
 SG_ LV_Fault_APPS_Implausibility : 54|1@1+ (1,0) [0|1] "" Vector__XXX
 SG_ LV_Fault_BPT_Upper : 53|1@1+ (1,0) [0|1] "" Vector__XXX
 SG_ LV_Fault_BPT_Lower : 52|1@1+ (1,0) [0|1] "" Vector__XXX
 SG_ LV_Fault_APPS2_Upper : 51|1@1+ (1,0) [0|1] "" Vector__XXX
 SG_ LV_Fault_APPS2_Lower : 50|1@1+ (1,0) [0|1] "" Vector__XXX
 SG_ LV_Fault_APPS1_Upper : 49|1@1+ (1,0) [0|1] "" Vector__XXX
 SG_ LV_Fault_APPS1_Lower : 48|1@1+ (1,0) [0|1] "" Vector__XXX
 SG_ LV_BPT_Front_2 : 32|16@1+ (1,0) [0|0] "" Vector__XXX
 SG_ LV_BPT_Front_1 : 16|16@1+ (1,0) [0|0] "" Vector__XXX
 SG_ LV_BPT_Rear : 0|16@1+ (1,0) [0|0] "" Vector__XXX

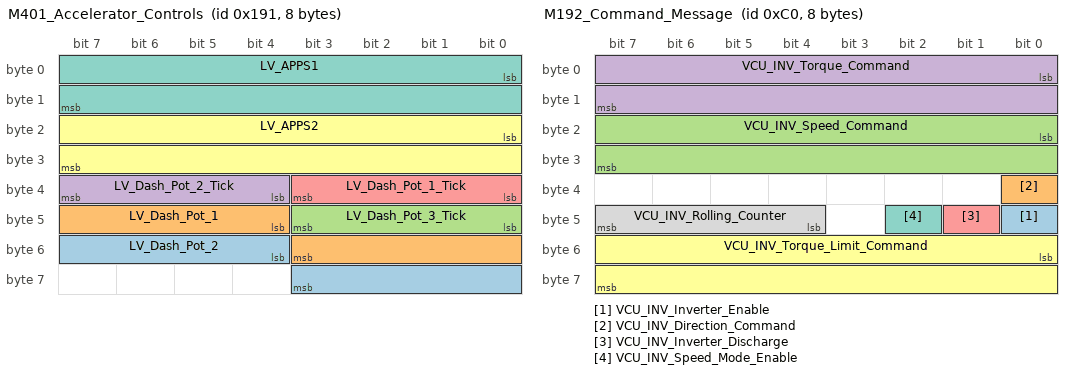
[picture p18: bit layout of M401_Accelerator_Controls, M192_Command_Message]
BO_ 401 M401_Accelerator_Controls: 8 LV
 SG_ LV_Dash_Pot_2 : 52|8@1+ (20,0) [0|5100] "" Vector__XXX
 SG_ LV_Dash_Pot_1 : 44|8@1+ (20,0) [0|5100] "" Vector__XXX
 SG_ LV_Dash_Pot_3_Tick : 40|4@1+ (1,0) [0|15] "" Vector__XXX
 SG_ LV_Dash_Pot_2_Tick : 36|4@1+ (1,0) [0|15] "" Vector__XXX
 SG_ LV_Dash_Pot_1_Tick : 32|4@1+ (1,0) [0|15] "" Vector__XXX
 SG_ LV_APPS2 : 16|16@1+ (1,0) [0|4095] "" Vector__XXX
 SG_ LV_APPS1 : 0|16@1+ (1,0) [0|4095] "" Vector__XXX

BO_ 173 M173_Modulation_And_Flux_Info: 8 INV
 SG_ INV_Iq_Command : 48|16@1- (0.1,0) [-3276.8|3276.7] "current:A" Vector__XXX
 SG_ INV_Id_Command : 32|16@1- (0.1,0) [-3276.8|3276.7] "current:A" Vector__XXX
 SG_ INV_Flux_Weakening_Output : 16|16@1- (0.1,0) [-3276.8|3276.7] "current:A" Vector__XXX
 SG_ INV_Modulation_Index : 0|16@1- (0.0001,0) [-3.2768|3.2767] "" Vector__XXX

BO_ 172 M172_Torque_And_Timer_Info: 8 INV
 SG_ INV_Power_On_Timer : 32|32@1+ (0.003,0) [0|12884800] "time:second" Vector__XXX
 SG_ INV_Torque_Feedback : 16|16@1- (0.1,0) [-3276.8|3276.7] "torque:N.m" Vector__XXX
 SG_ INV_Commanded_Torque : 0|16@1- (0.1,0) [-3276.8|3276.7] "torque:N.m" Vector__XXX

BO_ 194 M194_Read_Write_Param_Response: 8 INV
 SG_ INV_Parameter_Response_Write_OK : 16|1@1+ (1,0) [0|1] "" Vector__XXX
 SG_ INV_Parameter_Response_Data : 32|16@1- (1,0) [-32768|32767] "" Vector__XXX
 SG_ INV_Parameter_Response_Addr : 0|16@1+ (1,0) [0|65535] "" Vector__XXX

BO_ 193 M193_Read_Write_Param_Command: 8 Vector__XXX
 SG_ VCU_INV_Parameter_Data : 32|16@1- (1,0) [-32768|32767] "" Vector__XXX
 SG_ VCU_INV_Parameter_RW_Command : 16|1@1+ (1,0) [0|1] "" Vector__XXX
 SG_ VCU_INV_Parameter_Address : 0|16@1+ (1,0) [0|65535] "" Vector__XXX

BO_ 192 M192_Command_Message: 8 LV
 SG_ VCU_INV_Inverter_Enable : 40|1@1+ (1,0) [0|1] "" Vector__XXX
 SG_ VCU_INV_Direction_Command : 32|1@1+ (1,0) [0|1] "" Vector__XXX
 SG_ VCU_INV_Speed_Command : 16|16@1- (1,0) [-32768|32767] "angular_speed:rpm" Vector__XXX
 SG_ VCU_INV_Torque_Command : 0|16@1- (0.1,0) [-3276.8|3276.7] "torque:N.m" Vector__XXX
 SG_ VCU_INV_Inverter_Discharge : 41|1@1+ (1,0) [0|1] "" Vector__XXX
 SG_ VCU_INV_Torque_Limit_Command : 48|16@1- (0.1,0) [-3276.8|3276.7] "torque:N.m" Vector__XXX
 SG_ VCU_INV_Speed_Mode_Enable : 42|1@1+ (1,0) [0|1] "" Vector__XXX
 SG_ VCU_INV_Rolling_Counter : 44|4@1+ (1,0) [0|15] "" Vector__XXX

BO_ 171 M171_Fault_Codes: 8 INV
 SG_ INV_Run_Fault_Hi : 48|16@1+ (1,0) [0|65535] "" Vector__XXX
 SG_ INV_Post_Fault_Hi : 16|16@1+ (1,0) [0|65535] "" Vector__XXX
 SG_ INV_Run_Fault_Lo : 32|16@1+ (1,0) [0|65535] "" Vector__XXX
 SG_ INV_Post_Fault_Lo : 0|16@1+ (1,0) [0|65535] "" Vector__XXX

BO_ 170 M170_Internal_States: 8 INV
 SG_ INV_Direction_Command : 56|1@1+ (1,0) [0|1] "" Vector__XXX
 SG_ INV_Inverter_Enable_State : 48|1@1+ (1,0) [0|1] ""  LV
 SG_ INV_Relay_3_Status : 26|1@1+ (1,0) [0|1] "" Vector__XXX
 SG_ INV_Relay_4_Status : 27|1@1+ (1,0) [0|1] "" Vector__XXX
 SG_ INV_Relay_2_Status : 25|1@1+ (1,0) [0|1] "" Vector__XXX
 SG_ INV_Inverter_Run_Mode : 32|1@1+ (1,0) [0|1] "" Vector__XXX
 SG_ INV_Inverter_Command_Mode : 40|1@1+ (1,0) [0|1] "" Vector__XXX
 SG_ INV_Relay_1_Status : 24|1@1+ (1,0) [0|1] "" Vector__XXX
 SG_ INV_Inverter_State : 16|8@1+ (1,0) [0|255] "" Vector__XXX
 SG_ INV_VSM_State : 0|8@1+ (1,0) [0|15] "" Vector__XXX
 SG_ INV_Inverter_Enable_Lockout : 55|1@1+ (1,0) [0|1] "" Vector__XXX
 SG_ INV_Inverter_Discharge_State : 37|3@1+ (1,0) [0|7] "" Vector__XXX
 SG_ INV_Relay_5_Status : 28|1@1+ (1,0) [0|1] "" Vector__XXX
 SG_ INV_Relay_6_Status : 29|1@1+ (1,0) [0|1] "" Vector__XXX
 SG_ INV_BMS_Active : 57|1@1+ (1,0) [0|1] "" Vector__XXX
 SG_ INV_BMS_Torque_Limiting : 58|1@1+ (1,0) [0|1] "" Vector__XXX
 SG_ INV_PWM_Frequency : 8|8@1+ (1,0) [0|255] "" Vector__XXX
 SG_ INV_Limit_Max_Speed : 59|1@1+ (1,0) [0|1] "" Vector__XXX
 SG_ INV_Limit_Hot_Spot : 60|1@1+ (1,0) [0|1] "" Vector__XXX
 SG_ INV_Low_Speed_Limiting : 61|1@1+ (1,0) [0|1] "" Vector__XXX
 SG_ INV_Rolling_Counter : 44|4@1+ (1,0) [0|15] "" Vector__XXX
 SG_ INV_Limit_Coolant_Derating : 62|1@1+ (1,0) [0|1] "" Vector__XXX
 SG_ INV_Self_Sensing_Assist_Enable : 33|1@1+ (1,0) [0|1] "" Vector__XXX
 SG_ INV_Limit_Stall_Burst_Model : 63|1@1+ (1,0) [0|1] "" Vector__XXX
 SG_ INV_Burst_Model_Mode : 49|1@1+ (1,0) [0|1] "" Vector__XXX
 SG_ INV_Key_Switch_Start_Status : 54|1@1+ (1,0) [0|1] "" Vector__XXX

BO_ 169 M169_Internal_Voltages: 8 INV
 SG_ INV_Ref_Voltage_12_0 : 48|16@1- (0.01,0) [-327.68|327.67] "voltage:V" Vector__XXX
 SG_ INV_Ref_Voltage_5_0 : 32|16@1- (0.01,0) [-327.68|327.67] "voltage:V" Vector__XXX
 SG_ INV_Ref_Voltage_2_5 : 16|16@1- (0.01,0) [-327.68|327.67] "voltage:V" Vector__XXX
 SG_ INV_Ref_Voltage_1_5 : 0|16@1- (0.01,0) [-327.68|327.67] "voltage:V" Vector__XXX

BO_ 168 M168_Flux_ID_IQ_Info: 8 INV
 SG_ INV_Iq : 48|16@1- (0.1,0) [-3276.8|3276.7] "current:A" Vector__XXX
 SG_ INV_Id : 32|16@1- (0.1,0) [-3276.8|3276.7] "current:A" Vector__XXX
 SG_ INV_Vq_ff : 16|16@1- (0.1,0) [-3276.7|3276.7] "voltage:V" Vector__XXX
 SG_ INV_Vd_ff : 0|16@1- (0.1,0) [-3276.7|3276.7] "voltage:V" Vector__XXX

BO_ 167 M167_Voltage_Info: 8 INV
 SG_ INV_VBC_Vq_Voltage : 48|16@1- (0.1,0) [-3276.8|3276.7] "voltage:V" Vector__XXX
 SG_ INV_VAB_Vd_Voltage : 32|16@1- (0.1,0) [-3276.8|3276.7] "voltage:V" Vector__XXX
 SG_ INV_Output_Voltage : 16|16@1- (0.1,0) [-3276.8|3276.7] "voltage:V" Vector__XXX
 SG_ INV_DC_Bus_Voltage : 0|16@1- (0.1,0) [-3276.8|3276.7] "voltage:V" Vector__XXX

BO_ 166 M166_Current_Info: 8 INV
 SG_ INV_DC_Bus_Current : 48|16@1- (0.1,0) [-3276.8|3276.7] "current:A" Vector__XXX
 SG_ INV_Phase_C_Current : 32|16@1- (0.1,0) [-3276.8|3276.7] "current:A" Vector__XXX
 SG_ INV_Phase_B_Current : 16|16@1- (0.1,0) [-3276.8|3276.7] "current:A" Vector__XXX
 SG_ INV_Phase_A_Current : 0|16@1- (0.1,0) [-3276.8|3276.7] "current:A" Vector__XXX

BO_ 165 M165_Motor_Position_Info: 8 INV
 SG_ INV_Delta_Resolver_Filtered : 48|16@1- (0.1,0) [-3276.8|3276.7] "angle:deg" Vector__XXX
 SG_ INV_Electrical_Output_Frequency : 32|16@1- (0.1,0) [-3276.8|3276.7] "frequency:Hz" Vector__XXX
 SG_ INV_Motor_Speed : 16|16@1- (1,0) [-32768|32767] "angular_speed:rpm" Vector__XXX
 SG_ INV_Motor_Angle_Electrical : 0|16@1+ (0.1,0) [0|6553.5] "angle:deg" Vector__XXX

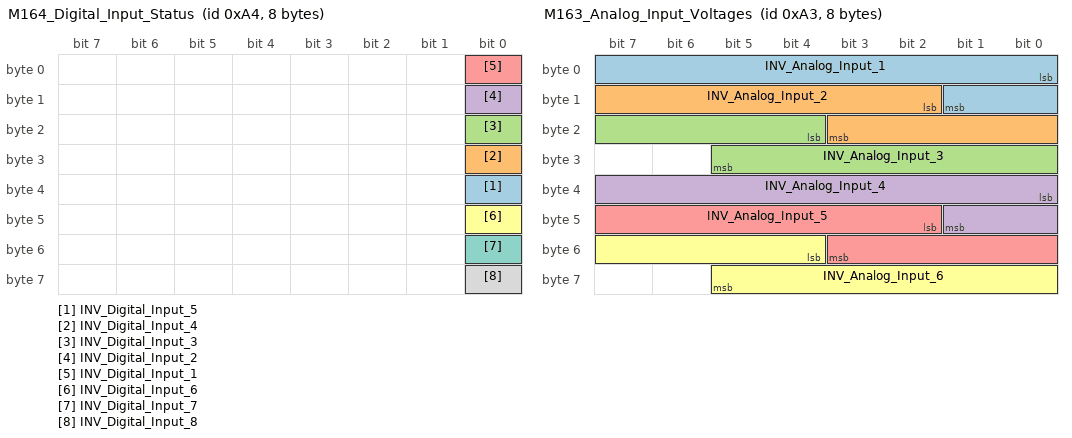
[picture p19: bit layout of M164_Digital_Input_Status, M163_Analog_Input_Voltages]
BO_ 164 M164_Digital_Input_Status: 8 INV
 SG_ INV_Digital_Input_5 : 32|1@1+ (1,0) [0|1] "" Vector__XXX
 SG_ INV_Digital_Input_4 : 24|1@1+ (1,0) [0|1] "" Vector__XXX
 SG_ INV_Digital_Input_3 : 16|1@1+ (1,0) [0|1] "" Vector__XXX
 SG_ INV_Digital_Input_2 : 8|1@1+ (1,0) [0|1] "" Vector__XXX
 SG_ INV_Digital_Input_1 : 0|1@1+ (1,0) [0|1] "" Vector__XXX
 SG_ INV_Digital_Input_6 : 40|1@1+ (1,0) [0|1] "" Vector__XXX
 SG_ INV_Digital_Input_7 : 48|1@1+ (1,0) [0|1] "" Vector__XXX
 SG_ INV_Digital_Input_8 : 56|1@1+ (1,0) [0|1] "" Vector__XXX

BO_ 163 M163_Analog_Input_Voltages: 8 INV
 SG_ INV_Analog_Input_1 : 0|10@1+ (0.01,0) [0|10.23] "voltage:V" Vector__XXX
 SG_ INV_Analog_Input_2 : 10|10@1+ (0.01,0) [0|10.23] "voltage:V" Vector__XXX
 SG_ INV_Analog_Input_3 : 20|10@1+ (0.01,0) [0|10.23] "voltage:V" Vector__XXX
 SG_ INV_Analog_Input_4 : 32|10@1+ (0.01,0) [0|10.23] "voltage:V" Vector__XXX
 SG_ INV_Analog_Input_5 : 42|10@1+ (0.01,0) [0|10.23] "voltage:V" Vector__XXX
 SG_ INV_Analog_Input_6 : 52|10@1+ (0.01,0) [0|10.23] "voltage:V" Vector__XXX

BO_ 162 M162_Temperature_Set_3: 8 INV
 SG_ INV_Torque_Shudder : 48|16@1- (0.1,0) [-3276.8|3276.7] "torque:N.m" Vector__XXX
 SG_ INV_Motor_Temp : 32|16@1- (0.1,0) [-3276.8|3276.7] "temperature:C" Vector__XXX
 SG_ INV_Hot_Spot_Temp : 16|16@1- (0.1,0) [-3276.8|3276.7] "temperature:C" Vector__XXX
 SG_ INV_Coolant_Temp : 0|16@1- (0.1,0) [-3276.8|3276.7] "temperature:C" Vector__XXX

BO_ 161 M161_Temperature_Set_2: 8 INV
 SG_ INV_RTD2_Temperature : 32|16@1- (0.1,0) [-3276.8|3276.7] "temperature:C" Vector__XXX
 SG_ INV_RTD1_Temperature : 16|16@1- (0.1,0) [-3276.8|3276.7] "temperature:C" Vector__XXX
 SG_ INV_Control_Board_Temp : 0|16@1- (0.1,0) [-3276.8|3276.7] "temperature:C" Vector__XXX
 SG_ INV_Stall_Burst_Model_Temp : 48|16@1- (0.1,0) [-3276.8|3276.7] "temperature:C" Vector__XXX

BO_ 160 M160_Temperature_Set_1: 8 INV
 SG_ INV_Gate_Driver_Board_Temp : 48|16@1- (0.1,0) [-3276.8|3276.7] "temperature:C" Vector__XXX
 SG_ INV_Module_C_Temp : 32|16@1- (0.1,0) [-3276.8|3276.7] "temperature:C" Vector__XXX
 SG_ INV_Module_B_Temp : 16|16@1- (0.1,0) [-3276.8|3276.7] "temperature:C" Vector__XXX
 SG_ INV_Module_A_Temp : 0|16@1- (0.1,0) [-3276.8|3276.7] "temperature:C" Vector__XXX

BO_ 174 M174_Firmware_Info: 8 INV
 SG_ INV_Project_Code_EEP_Ver : 0|16@1+ (1,0) [0|65535] "" Vector__XXX
 SG_ INV_SW_Version : 16|16@1+ (1,0) [0|65535] "" Vector__XXX
 SG_ INV_DateCode_MMDD : 32|16@1+ (1,0) [0|65535] "" Vector__XXX
 SG_ INV_DateCode_YYYY : 48|16@1+ (1,0) [0|65535] "" Vector__XXX

BO_ 175 M175_Diag_Data_Message: 8 INV
 SG_ INV_Diag_Record : 0|8@1+ (1,0) [0|160] "" Vector__XXX
 SG_ INV_Diag_Segment M : 8|8@1+ (1,0) [0|5] "" Vector__XXX
 SG_ INV_Diag_Gamma_Resolver m0 : 16|16@1- (0.1,0) [0|360] "angle:deg" Vector__XXX
 SG_ INV_Diag_Gamma_Observer m0 : 32|16@1- (0.1,0) [0|360] "angle:deg" Vector__XXX
 SG_ INV_Diag_Sin_Used m0 : 48|16@1- (1,0) [-5|5] "voltage:V" Vector__XXX
 SG_ INV_Diag_Cos_Used m1 : 16|16@1- (1,0) [-5|5] "voltage:V" Vector__XXX
 SG_ INV_Diag_Ia m1 : 32|16@1- (0.1,0) [-2000|2000] "current:A" Vector__XXX
 SG_ INV_Diag_Ib m1 : 48|16@1- (0.1,0) [-2000|2000] "current:A" Vector__XXX
 SG_ INV_Diag_Ic m2 : 16|16@1- (0.1,0) [-2000|2000] "current:A" Vector__XXX
 SG_ INV_Diag_Vdc m2 : 32|16@1- (0.1,0) [0|1000] "voltage:V" Vector__XXX
 SG_ INV_Diag_Iq_cmd m2 : 48|16@1- (0.1,0) [-2000|2000] "current:A" Vector__XXX
 SG_ INV_Diag_Id_cmd m3 : 16|16@1- (0.1,0) [-2000|2000] "current:A" Vector__XXX
 SG_ INV_Diag_Mod_Index m3 : 32|16@1- (0.0001,0) [0|2] "" Vector__XXX
 SG_ INV_Diag_FW_Output m3 : 48|16@1- (0.1,0) [-2000|2000] "current:A" Vector__XXX
 SG_ INV_Diag_Vq_Cmd m4 : 16|16@1- (0.1,0) [-1000|1000] "voltage:V" Vector__XXX
 SG_ INV_Diag_Vd_Cmd m4 : 32|16@1- (0.1,0) [-1000|1000] "voltage:V" Vector__XXX
 SG_ INV_Diag_Vqs_Cmd m4 : 48|16@1- (0.1,0) [-1000|1000] "voltage:V" Vector__XXX
 SG_ INV_Diag_PWM_Freq m5 : 16|16@1+ (1,0) [0|24] "frequency:kHz" Vector__XXX
 SG_ INV_Diag_Run_Faults_Lo m5 : 32|16@1+ (1,0) [0|65535] "" Vector__XXX
 SG_ INV_Diag_Run_Faults_Hi m5 : 48|16@1+ (1,0) [0|65535] "" Vector__XXX

BO_ 176 M176_Fast_Info: 8 INV
 SG_ INV_Fast_Torque_Command : 0|16@1- (0.1,0) [-3276.8|32767.7] "torque:N.m" Vector__XXX
 SG_ INV_Fast_Torque_Feedback : 16|16@1- (0.1,0) [-3276.8|3276.7] "torque:N.m" Vector__XXX
 SG_ INV_Fast_Motor_Speed : 32|16@1- (1,0) [-32768|32767] "angular_speed:rpm" Vector__XXX
 SG_ INV_Fast_DC_Bus_Voltage : 48|16@1- (0.1,0) [-3276.8|3276.7] "voltage:V" Vector__XXX

BO_ 177 M177_Torque_Capability: 8 INV
 SG_ INV_Torque_Capability : 0|16@1+ (0.1,0) [0|6553.6] "torque:N.m" Vector__XXX

CM_ SG_ 173 INV_Iq_Command "The commanded Q-axis current";
CM_ SG_ 173 INV_Id_Command "The commanded D-axis current";
CM_ SG_ 173 INV_Flux_Weakening_Output "This is the current output of the flux regulator.";
CM_ SG_ 173 INV_Modulation_Index "This is the modulation index. The scale factor is x100. To get the actual modulation index divide the value by 100.";
CM_ SG_ 172 INV_Power_On_Timer "Updated every 3 msec. This will roll over in approximately 150 days!";
CM_ SG_ 172 INV_Torque_Feedback "Estimated motor torque feedback";
CM_ SG_ 172 INV_Commanded_Torque "The commanded Torque";
CM_ BO_ 194 "To write a parameter use message 0x0C1 with byte #2 set to 1 (write). 
To read a parameter use message 0x0C1 with byte #2 to set 0 (read). ";
CM_ SG_ 194 INV_Parameter_Response_Write_OK "0=Write failure, 1=Success";
CM_ SG_ 194 INV_Parameter_Response_Data "Data from parameter message.  All data is 16 bits and is contained in bytes 4 and 5. Bytes 6 and 7 should be ignored.";
CM_ SG_ 194 INV_Parameter_Response_Addr "Address of parameter response message data.";
CM_ BO_ 193 "To write a parameter use message 0x0C1 with byte #2 set to 1 (write). 
To read a parameter use message 0x0C1 with byte #2 to set 0 (read). ";
CM_ SG_ 193 VCU_INV_Parameter_Data "Data to be written.  All data is 16 bits and is contained in bytes 4 and 5.";
CM_ SG_ 193 VCU_INV_Parameter_RW_Command "0=Read, 1=Write";
CM_ SG_ 193 VCU_INV_Parameter_Address "Address of parameter to be written or read.";
CM_ BO_ 192 "The command message is used to transmit data to the controller. This message is sent from a user supplied external controller to the PMxxx controller.";
CM_ SG_ 192 VCU_INV_Inverter_Enable "0=Inverter OFF, 1 = Inverter ON";
CM_ SG_ 192 VCU_INV_Direction_Command "0=Reverse, 1=Forward.  Forward is positive motor speed.";
CM_ SG_ 192 VCU_INV_Speed_Command "Speed command used when in speed mode";
CM_ SG_ 192 VCU_INV_Torque_Command "Torque command when in torque mode";
CM_ SG_ 192 VCU_INV_Inverter_Discharge "0=Discharge Disable,1=Discharge Enable";
CM_ SG_ 192 VCU_INV_Torque_Limit_Command "Torque Limit, set to 0 to keep default";
CM_ SG_ 192 VCU_INV_Speed_Mode_Enable "0 = No change to mode, 1 = change to speed mode from torque mode";
CM_ SG_ 192 VCU_INV_Rolling_Counter "Rolling Counter sent to inverter.  If used increment count with each message sent.  Otherwise can be set to 0.";
CM_ SG_ 171 INV_Run_Fault_Hi "Each bit represents a fault. Please refer to PM100 Users Manual for details.";
CM_ SG_ 171 INV_Post_Fault_Hi "Each bit represents a fault. Please refer to PM100 Users Manual for details.";
CM_ SG_ 171 INV_Run_Fault_Lo "Each bit represents a fault. Please refer to PM100 Users Manual for details.";
CM_ SG_ 171 INV_Post_Fault_Lo "Each bit represents a fault. Please refer to PM100 Users Manual for details.";
CM_ SG_ 170 INV_Direction_Command "1 = Forward
0 = 'Reverse' if inverter enabled  & 'Stopped' if inverter is disabled";
CM_ SG_ 170 INV_Inverter_Enable_State "0=Inverter Disabled, 
1=Inverter Enabled";
CM_ SG_ 170 INV_Relay_3_Status "0=OFF, 1=ON";
CM_ SG_ 170 INV_Relay_4_Status "0=OFF, 1=ON";
CM_ SG_ 170 INV_Relay_2_Status "0=OFF, 1=ON";
CM_ SG_ 170 INV_Inverter_Run_Mode "0=Torque Mode, 1=Speed Mode";
CM_ SG_ 170 INV_Inverter_Command_Mode "0=CAN mode, 1=VSM mode";
CM_ SG_ 170 INV_Relay_1_Status "0=OFF, 1=ON";
CM_ SG_ 170 INV_Inverter_State "Different states for the inverter state machine";
CM_ SG_ 170 INV_VSM_State "Different states for the vehicle state machine";
CM_ SG_ 170 INV_Inverter_Enable_Lockout "0=Lockout Disabled, 1=Lockout Enabled";
CM_ SG_ 170 INV_Inverter_Discharge_State "0 = Disabled, 1 = Enabled, 2 = Speed Check, 3 = Active, 4 = Complete, 5 = Error, 6 = Override, 7 = Timeout";
CM_ SG_ 170 INV_Relay_5_Status "0=OFF, 1=ON";
CM_ SG_ 170 INV_Relay_6_Status "0=OFF, 1=ON";
CM_ SG_ 170 INV_BMS_Active "0 = BMS Not Active, 1 = BMS Active";
CM_ SG_ 170 INV_BMS_Torque_Limiting "0 = Not Limiting, 1 = Limiting";
CM_ SG_ 170 INV_PWM_Frequency "The current active PWM frequency";
CM_ SG_ 170 INV_Limit_Max_Speed "Indicates that torque is being modified to limit the speed.";
CM_ SG_ 170 INV_Limit_Hot_Spot "Indicates that torque is being limited to limit the hot spot temp";
CM_ SG_ 170 INV_Low_Speed_Limiting "Indicates that motor current is being limited due to low motor electrical frequency.";
CM_ SG_ 170 INV_Rolling_Counter "Rolling Counter value";
CM_ SG_ 170 INV_Limit_Coolant_Derating "0 = Not limiting, 1 = Limiting";
CM_ SG_ 170 INV_Self_Sensing_Assist_Enable "1 = Self Sensing Assist Enabled, 0 = Self Sensing Assist Disabled";
CM_ SG_ 170 INV_Limit_Stall_Burst_Model "0 = Not limiting, 1 = Limiting";
CM_ SG_ 170 INV_Burst_Model_Mode "0 = Stall, 1 = High Speed";
CM_ SG_ 170 INV_Key_Switch_Start_Status "0 = OFF, 1 = ON";
CM_ SG_ 169 INV_Ref_Voltage_12_0 "12V Input Voltage";
CM_ SG_ 169 INV_Ref_Voltage_5_0 "Transducer voltage";
CM_ SG_ 169 INV_Ref_Voltage_2_5 "Internal reference voltage";
CM_ SG_ 169 INV_Ref_Voltage_1_5 "Internal reference voltage";
CM_ SG_ 168 INV_Iq "The measured Iq current";
CM_ SG_ 168 INV_Id "The measured Id current";
CM_ SG_ 168 INV_Vq_ff "The q-axis voltage feedforward";
CM_ SG_ 168 INV_Vd_ff "The d-axis voltage feedforward";
CM_ SG_ 167 INV_VBC_Vq_Voltage "Measured value of the voltage between Phase B and Phase C";
CM_ SG_ 167 INV_VAB_Vd_Voltage "Measured value of the voltage betwen phase A and Phase B";
CM_ SG_ 167 INV_Output_Voltage "The calculated value of the output voltage, in peak line-neutral volts";
CM_ SG_ 167 INV_DC_Bus_Voltage "The actual measured value of the DC bus voltage";
CM_ SG_ 166 INV_DC_Bus_Current "The Calculated DC Bus Current";
CM_ SG_ 166 INV_Phase_C_Current "The measured value of Phase C current";
CM_ SG_ 166 INV_Phase_B_Current "The measured value of Phase B current";
CM_ SG_ 166 INV_Phase_A_Current "The measured value of Phase A current";
CM_ SG_ 165 INV_Delta_Resolver_Filtered "Used in calibration of resolver angle adjustment.";
CM_ SG_ 165 INV_Electrical_Output_Frequency "The actual electrical frequency of the inverter";
CM_ SG_ 165 INV_Motor_Speed "The measured speed of the motor";
CM_ SG_ 165 INV_Motor_Angle_Electrical "The Electrical Angle of the motor as read by the encoder or resolver";
CM_ SG_ 164 INV_Digital_Input_5 "Status of Digital Input #5";
CM_ SG_ 164 INV_Digital_Input_4 "Status of Digital Input #4";
CM_ SG_ 164 INV_Digital_Input_3 "Status of Digital Input #3";
CM_ SG_ 164 INV_Digital_Input_2 "Status of Digital Input #2";
CM_ SG_ 164 INV_Digital_Input_1 "Status of Digital Input #1";
CM_ SG_ 164 INV_Digital_Input_6 "Status of Digital Input #6";
CM_ SG_ 164 INV_Digital_Input_7 "Status of Digital Input #7";
CM_ SG_ 164 INV_Digital_Input_8 "Status of Digital Input #8";
CM_ SG_ 163 INV_Analog_Input_1 "Voltage on Analog Input #1";
CM_ SG_ 163 INV_Analog_Input_2 "Voltage on Analog Input #2";
CM_ SG_ 163 INV_Analog_Input_3 "Voltage on Analog Input #3";
CM_ SG_ 163 INV_Analog_Input_4 "Voltage on Analog Input #4";
CM_ SG_ 163 INV_Analog_Input_5 "Voltage on Analog Input #5";
CM_ SG_ 163 INV_Analog_Input_6 "Voltage on Analog Input #6";
CM_ SG_ 162 INV_Torque_Shudder "Shudder compensation value of torque";
CM_ SG_ 162 INV_Motor_Temp "Motor Temperature Sensor";
CM_ SG_ 162 INV_Hot_Spot_Temp "Estimated inverter hot spot temperature";
CM_ SG_ 162 INV_Coolant_Temp "Estimated Coolant Temperature";
CM_ SG_ 161 INV_RTD2_Temperature "RTD input 2 (PT1000) Temperature";
CM_ SG_ 161 INV_RTD1_Temperature "RTD input 1 (PT1000) Temperature";
CM_ SG_ 161 INV_Control_Board_Temp "Control Board Temperature";
CM_ SG_ 161 INV_Stall_Burst_Model_Temp "Hottest temperature estimated from the stall burst thermal model feature";
CM_ SG_ 160 INV_Gate_Driver_Board_Temp "Gate Driver Board Temperature";
CM_ SG_ 160 INV_Module_C_Temp "IGBT Module C Temperature";
CM_ SG_ 160 INV_Module_B_Temp "IGBT Module B Temperature";
CM_ SG_ 160 INV_Module_A_Temp "IGBT Module A Temperature";
CM_ BO_ 176 "To enable fast message set CAN ACTIVE MSGS HI WORD to 0xFFFE.  Setting to default value of 0xFFFF will disable the fast message.";
CM_ SG_ 176 INV_Fast_Torque_Command "The commanded torque";
CM_ SG_ 176 INV_Fast_Torque_Feedback "The estimated torque";
CM_ SG_ 176 INV_Fast_Motor_Speed "Motor speed";
CM_ SG_ 176 INV_Fast_DC_Bus_Voltage "DC Bus Voltage";
CM_ SG_ 177 INV_Torque_Capability "The torque capability of the inverter given the current operating point.";
BA_DEF_ BO_  "GenMsgCycleTime" INT 0 100000;
BA_DEF_  "BusType" STRING ;
BA_DEF_DEF_  "GenMsgCycleTime" 0;
BA_DEF_DEF_  "BusType" "CAN";
BA_ "GenMsgCycleTime" BO_ 172 10;
BA_ "GenMsgCycleTime" BO_ 192 10;
BA_ "GenMsgCycleTime" BO_ 171 100;
BA_ "GenMsgCycleTime" BO_ 170 100;
BA_ "GenMsgCycleTime" BO_ 169 100;
BA_ "GenMsgCycleTime" BO_ 168 10;
BA_ "GenMsgCycleTime" BO_ 167 10;
BA_ "GenMsgCycleTime" BO_ 166 10;
BA_ "GenMsgCycleTime" BO_ 165 10;
BA_ "GenMsgCycleTime" BO_ 164 10;
BA_ "GenMsgCycleTime" BO_ 163 10;
BA_ "GenMsgCycleTime" BO_ 162 100;
BA_ "GenMsgCycleTime" BO_ 161 100;
BA_ "GenMsgCycleTime" BO_ 160 100;
BA_ "GenMsgCycleTime" BO_ 176 3;
BA_ "GenMsgCycleTime" BO_ 177 10;
VAL_ 192 VCU_INV_Inverter_Enable 0 "Turn the inverter OFF" 1 "Turn the Inverter ON" ;
VAL_ 192 VCU_INV_Direction_Command 0 "CW" 1 "CCW" ;
VAL_ 192 VCU_INV_Inverter_Discharge 0 "Discharge Disable" 1 "Discharge Enable (if EEPROM parameter is set)" ;
VAL_ 170 INV_Inverter_State 0 "Power up" 1 "Stop" 2 "Open Loop" 3 "Closed Loop" 4 "Internal State" 5 "Internal State" 6 "Internal State" 7 "Internal State" 8 "Idle Run" 9 "Idle Stop" 10 "Internal State" 11 "Intern State" 12 "Internal State" ;
VAL_ 170 INV_VSM_State 0 "VSM Start State" 1 "Pre-Charge Init state" 2 "pre-charge active state" 3 "pre-charge complete state" 4 "VSM wait state" 5 "VSM ready state" 6 "Motor Running State" 7 "blink fault code state" 14 "Shutdown state for Key Switch Mode 1" 15 "Reset the inverter" ;
VAL_ 170 INV_Inverter_Discharge_State 0 "Disabled" 1 "Enabled" 2 "Speed Check" 3 "Active" 4 "Complete" 5 "Error" 6 "Override" 7 "Timeout" ;
VAL_ 170 INV_Limit_Stall_Burst_Model 0 "Not Limiting" 1 "Limiting" ;
VAL_ 170 INV_Burst_Model_Mode 0 "Stall" 1 "High Speed" ;
